[part 2 of 2: packages /ISignalGroups/IMU_INTERNAL/PKG_IMU_INTERNAL/Meas_IMU_B_ST3 to /CryptoDevelopmentKeys]
AUTOSAR XML (schema 00049)
package /ISignalGroups/IMU_INTERNAL/PKG_IMU_INTERNAL/Meas_IMU_B_ST3
  i signal group Meas_IMU_B_ST3_9b4k5uqw790qkzbaaznvwy423: i-signal=[Meas_IMU_B_01_ST3, Meas_IMU_B_02_ST3, Meas_IMU_B_03_ST3, Meas_IMU_B_04_ST3, Meas_IMU_B_05_ST3, Meas_IMU_B_06_ST3, Meas_IMU_B_07_ST3, Meas_IMU_B_08_ST3, Meas_IMU_B_09_ST3, Meas_IMU_B_10_ST3, Meas_IMU_B_11_ST3, Meas_IMU_B_12_ST3, Meas_IMU_B_13_ST3, Meas_IMU_B_14_ST3, Meas_IMU_B_15_ST3, Meas_IMU_B_16_ST3, Meas_IMU_B_17_ST3, Meas_IMU_B_18_ST3, Meas_IMU_B_19_ST3, Meas_IMU_B_20_ST3, Meas_IMU_B_21_ST3, Meas_IMU_B_22_ST3, Meas_IMU_B_23_ST3, Meas_IMU_B_24_ST3, Meas_IMU_B_25_ST3, Meas_IMU_B_26_ST3, Meas_IMU_B_27_ST3, Meas_IMU_B_28_ST3, Meas_IMU_B_29_ST3, Meas_IMU_B_30_ST3, Meas_IMU_B_31_ST3, Meas_IMU_B_32_ST3, Meas_IMU_B_33_ST3, Meas_IMU_B_34_ST3, Meas_IMU_B_35_ST3, Meas_IMU_B_36_ST3, Meas_IMU_B_37_ST3, Meas_IMU_B_38_ST3, Meas_IMU_B_39_ST3, Meas_IMU_B_40_ST3, Meas_IMU_B_41_ST3, Meas_IMU_B_42_ST3, Meas_IMU_B_43_ST3, Meas_IMU_B_44_ST3, Meas_IMU_B_45_ST3, Meas_IMU_B_46_ST3, Meas_IMU_B_47_ST3, Meas_IMU_B_48_ST3, Meas_IMU_B_49_ST3, Meas_IMU_B_50_ST3, Meas_IMU_B_51_ST3, Meas_IMU_B_52_ST3, Meas_IMU_B_53_ST3, Meas_IMU_B_54_ST3, Meas_IMU_B_55_ST3, Meas_IMU_B_56_ST3, Meas_IMU_B_57_ST3, Meas_IMU_B_58_ST3, Meas_IMU_B_59_ST3, Meas_IMU_B_60_ST3, Meas_IMU_B_61_ST3, Meas_IMU_B_62_ST3, Meas_IMU_B_63_ST3, Meas_IMU_B_64_ST3], system-signal-group=Meas_IMU_B_ST3_9b4k5uqw790qkzbaaznvwy423  # Messbotschaft (degraded) / Measurement (degraded)
package /ISignalGroups/IMU_INTERNAL/PKG_IMU_INTERNAL/PT4_PTCoor4_ST3
  i signal group PT4_PTCoor4_Pr5_ST3_af4fxb1ykieox3itqdfzs0kpb: com-based-signal-group-transformations=BaseTrans_Profile_5_4, i-signal=[CRC_PT4_PTCoor4_Pr5_ST3, PT4_PTCoor_EngStartPN14_Stat_ST3, PT4_PTCoor_PT_Rdy_ST3, PT4_PTCoor_SSA_EngSp_ST3, Rsrv1_PT4_PTCoor_PT_Rdy_Pr5_ST3, SQC_PT4_PTCoor4_Pr5_ST3], system-signal-group=PT4_PTCoor4_Pr5_ST3_af4fxb1ykieox3itqdfzs0kpb, end-to-end-transformation-i-signal-props{transformer=E2E_Profile_5, data-ids=196, data-length=32}  # PT4_PTCoor4_Pr5_ST3 (degraded)
package /ISignalGroups/IMU_INTERNAL/PKG_IMU_INTERNAL/ROE_IMU_B_ST3
  i signal group ROE_IMU_B_ST3_7zavpp3siu6s2eitdaqxg7lwg: i-signal=[ROE_0_IMU_B_ST3, ROE_1_IMU_B_ST3, ROE_2_IMU_B_ST3, ROE_3_IMU_B_ST3, ROE_4_IMU_B_ST3, ROE_5_IMU_B_ST3, ROE_6_IMU_B_ST3, ROE_7_IMU_B_ST3], system-signal-group=ROE_IMU_B_ST3_7zavpp3siu6s2eitdaqxg7lwg  # Ereignis-Antwort (degraded) / Response on Event (degraded)
package /ISignalGroups/IMU_INTERNAL/PKG_IMU_INTERNAL/VSS_TP_Auth_ST3
  i signal group VSS_TP_Auth_ST3_6j4id7sghlvlbroli4wjozjik: i-signal=[VSS_TP_Auth_0_ST3, VSS_TP_Auth_1_ST3, VSS_TP_Auth_2_ST3, VSS_TP_Auth_3_ST3, VSS_TP_Auth_4_ST3, VSS_TP_Auth_5_ST3, VSS_TP_Auth_6_ST3, VSS_TP_Auth_7_ST3], system-signal-group=VSS_TP_Auth_ST3_6j4id7sghlvlbroli4wjozjik  # VSS-Transportprotokoll für Authentifizierung (degraded) / Vehicle Security System Transport Protocol for authentication broadcast (degraded)
package /ISignalGroups/IMU_INTERNAL/PKG_IMU_INTERNAL/VSS_TP_RealTmOffset_ST3
  i signal group VSS_TP_RealTmOffset_ST3_1t7vc44gftc0wv35k5kgc2in9: i-signal=[VSS_TP_RealTmOffset_0_ST3, VSS_TP_RealTmOffset_1_ST3, VSS_TP_RealTmOffset_2_ST3, VSS_TP_RealTmOffset_3_ST3, VSS_TP_RealTmOffset_4_ST3, VSS_TP_RealTmOffset_5_ST3, VSS_TP_RealTmOffset_6_ST3, VSS_TP_RealTmOffset_7_ST3], system-signal-group=VSS_TP_RealTmOffset_ST3_1t7vc44gftc0wv35k5kgc2in9  # VSS-Transportprotokoll für Echtzeit-Offset (degraded) / Vehicle Security System Transport Protocol for real time offset broadcast (degraded)
package /ISignalGroups/IMU_INTERNAL/PKG_IMU_INTERNAL/VSS_TP_SecTickCount_Lvl1_ST3
  i signal group VSS_TP_SecTickCount_Lvl1_ST3_mzmfdqtqz5kvv1kfpvg0kql3: i-signal=[VSS_TP_SecTickCount_Lvl1_0_ST3, VSS_TP_SecTickCount_Lvl1_1_ST3, VSS_TP_SecTickCount_Lvl1_2_ST3, VSS_TP_SecTickCount_Lvl1_3_ST3, VSS_TP_SecTickCount_Lvl1_4_ST3, VSS_TP_SecTickCount_Lvl1_5_ST3, VSS_TP_SecTickCount_Lvl1_6_ST3, VSS_TP_SecTickCount_Lvl1_7_ST3], system-signal-group=VSS_TP_SecTickCount_Lvl1_ST3_mzmfdqtqz5kvv1kfpvg0kql3  # VSS-Transportprotokoll für sichere Zeit Stufe 1 (degraded) / Vehicle Security System Transport Protocol for secure tick count level #1 (degraded)
package /ISignalGroups/IMU_INTERNAL/PKG_IMU_INTERNAL/VSS_TP_SharedSecret_ST3
  i signal group VSS_TP_SharedSecret_ST3_8pj4t8t4rm3tw3pk5hj7vonti: i-signal=[VSS_TP_SharedSecret_0_ST3, VSS_TP_SharedSecret_1_ST3, VSS_TP_SharedSecret_2_ST3, VSS_TP_SharedSecret_3_ST3, VSS_TP_SharedSecret_4_ST3, VSS_TP_SharedSecret_5_ST3, VSS_TP_SharedSecret_6_ST3, VSS_TP_SharedSecret_7_ST3], system-signal-group=VSS_TP_SharedSecret_ST3_8pj4t8t4rm3tw3pk5hj7vonti  # VSS-Transportprotokoll für gemeinsames Geheimnis (degraded) / Vehicle Security System Transport Protocol for shared secret broadcast (degraded)
package /ISignalGroups/IMU_INTERNAL/PKG_IMU_INTERNAL/VSS_TP_VIN_ST3
  i signal group VSS_TP_VIN_ST3_bz1xsv84cxzl09j028gn39p69: i-signal=[VSS_TP_VIN_0_ST3, VSS_TP_VIN_1_ST3, VSS_TP_VIN_2_ST3, VSS_TP_VIN_3_ST3, VSS_TP_VIN_4_ST3, VSS_TP_VIN_5_ST3, VSS_TP_VIN_6_ST3, VSS_TP_VIN_7_ST3], system-signal-group=VSS_TP_VIN_ST3_bz1xsv84cxzl09j028gn39p69  # VSS-Transportprotokoll für Fahrzeugidentifikationsnummer (degraded) / Vehicle Security System Transport Protocol for Vehicle Identification Number (degraded)
package /SecureCommunicationPropsSet
  secure communication props set XDIS_singleton_SecCommPropsSet
    secure communication authentication props SECOC_AP_CMAC_AES_128_24: auth-info-tx-length=24
    secure communication freshness props SECOC_FP_10000_40_8_true: freshness-timestamp-time-period-factor=10000, freshness-value-length=40, freshness-value-tx-length=8, use-freshness-timestamp=true
package /CommunicationClusters/IMU_INTERNAL
  can cluster IMU_INTERNAL: baudrate=500000, protocol-name=CAN, protocol-version=can2.0b, can-fd-baudrate=1000000
    can physical channel IMU_INTERNAL: comm-connectors=[IMU_A_IMU_INTERNAL_6hr0dxrs6bxnusth9n7j0x4yv, IMU_B_IMU_INTERNAL_949amicgr3ot53d5rms7k8b3w]
      frame FBL_CFG_Star3_ST3: id 0x68, from IMU_A, to IMU_B, frame-length=1, can-addressing-mode=STANDARD, can-frame-rx-behavior=CAN-20, can-frame-tx-behavior=CAN-20
        pdu FBL_Cfg_Star3_ST3: length=1, transmission-mode-true-timing=cyclic-timing=time-period=0.2, unused-bit-pattern=255  # FBL Konfigurationsinfo für Star3 / FBL configuration info for Star3
          signal Platform_Stat_Star3: start 0, 8 bit, little-endian, data-type-policy=OVERRIDE, i-signal-type=PRIMITIVE, init-value=4, base-type=uint8, invalid-value=255, compu-method=c08_Platform_Stat, data-constr=c08_Platform_Stat, transfer-property=PENDING, to IMU_B  # Plattformstatus / Platform state
      frame GTS_Main_CAN_ST3: id 0x79, from IMU_A, to IMU_B, frame-length=8, can-addressing-mode=STANDARD, can-frame-rx-behavior=CAN-FD, can-frame-tx-behavior=CAN-FD  # Status Uhrsynchronisation / Clock synchronisation state
        carries pdu GTS_Main_CAN_ST3: packing-byte-order=big-endian, start-position=7
        general purpose pdu GTS_Main_CAN_ST3: category=GLOBAL_TIME, length=8  # Status Uhrsynchronisation / Clock synchronisation state
      frame Ign_Stat_ST3: id 0x7F, from IMU_A, to IMU_B, frame-length=8, can-addressing-mode=STANDARD, can-frame-rx-behavior=CAN-FD, can-frame-tx-behavior=CAN-FD  # Zuendungsstatus / Ignition state
        secured i pdu Ign_Stat_ST3_secured: length=8, authentication-props=SECOC_AP_CMAC_AES_128_24, freshness-props=SECOC_FP_10000_40_8_true, payload=Ign_Stat_ST3_74u0yv4bzub4d7kkohk0jy10a, secure-communication-props={authentication-retries=0, data-id=28212, freshness-value-id=1}
      frame IMU_A_Output_Fast_ST3: id 0x2B3, from IMU_A, to IMU_B, frame-length=44, can-addressing-mode=STANDARD, can-frame-rx-behavior=CAN-FD, can-frame-tx-behavior=CAN-FD  # IMU A Output ST3
        secured i pdu IMU_A_Output_Fast_ST3_secured: length=44, authentication-props=SECOC_AP_CMAC_AES_128_24, freshness-props=SECOC_FP_10000_40_8_true, payload=IMU_A_Output_Fast_ST3_9j5x7ag429n202ymo68kf1vn0, secure-communication-props={authentication-retries=0, data-id=38379, freshness-value-id=1}
      frame BCS_Whl_Msg1_BTC_ST3: id 0x2BE, from IMU_A, to IMU_B, frame-length=24, can-addressing-mode=STANDARD, can-frame-rx-behavior=CAN-FD, can-frame-tx-behavior=CAN-FD  # BCS Whl Msg 1 ST3
        secured i pdu BCS_Whl_Msg1_BTC_ST3_secured: length=24, authentication-props=SECOC_AP_CMAC_AES_128_24, freshness-props=SECOC_FP_10000_40_8_true, payload=BCS_Whl_Msg1_BTC_ST3_c16k4ur8udt67j57b0rf78j53, secure-communication-props={authentication-retries=0, data-id=1270, freshness-value-id=1}
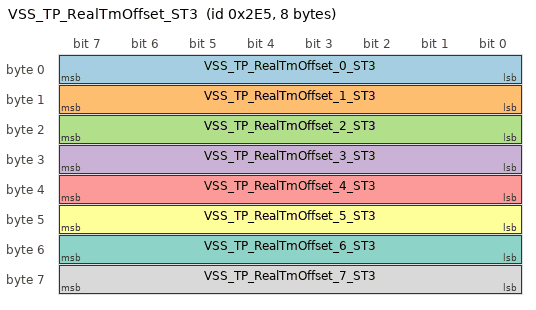
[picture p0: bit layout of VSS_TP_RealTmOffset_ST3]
      frame VSS_TP_RealTmOffset_ST3: id 0x2E5, from IMU_A, to IMU_B, frame-length=8, can-addressing-mode=STANDARD, can-frame-rx-behavior=CAN-FD, can-frame-tx-behavior=CAN-FD  # VSS-Transportprotokoll für Echtzeit-Offset / Vehicle Security System Transport Protocol for real time offset broadcast
        pdu VSS_TP_RealTmOffset_ST3: length=8, minimum-delay=0.02, transmission-mode-true-timing=event-controlled-timing=number-of-repetitions=0, unused-bit-pattern=255  # VSS-Transportprotokoll für Echtzeit-Offset / Vehicle Security System Transport Protocol for real time offset broadcast
          signal VSS_TP_RealTmOffset_0_ST3: start 0, 8 bit, little-endian, data-type-policy=OVERRIDE, i-signal-type=PRIMITIVE, init-value=255, base-type=uint8, data-constr=c08_UInt_SNA_na, to IMU_B  # VSS-Transportprotokoll für Echtzeit-Offset, Byte 0 / Vehicle Security System Transport Protocol for real time offset broadcast, Byte 0
          signal VSS_TP_RealTmOffset_1_ST3: start 8, 8 bit, little-endian, data-type-policy=OVERRIDE, i-signal-type=PRIMITIVE, init-value=255, base-type=uint8, data-constr=c08_UInt_SNA_na, to IMU_B  # VSS-Transportprotokoll für Echtzeit-Offset, Byte 1 / Vehicle Security System Transport Protocol for real time offset broadcast, Byte 1
          signal VSS_TP_RealTmOffset_2_ST3: start 16, 8 bit, little-endian, data-type-policy=OVERRIDE, i-signal-type=PRIMITIVE, init-value=255, base-type=uint8, data-constr=c08_UInt_SNA_na, to IMU_B  # VSS-Transportprotokoll für Echtzeit-Offset, Byte 2 / Vehicle Security System Transport Protocol for real time offset broadcast, Byte 2
          signal VSS_TP_RealTmOffset_3_ST3: start 24, 8 bit, little-endian, data-type-policy=OVERRIDE, i-signal-type=PRIMITIVE, init-value=255, base-type=uint8, data-constr=c08_UInt_SNA_na, to IMU_B  # VSS-Transportprotokoll für Echtzeit-Offset, Byte 3 / Vehicle Security System Transport Protocol for real time offset broadcast, Byte 3
          signal VSS_TP_RealTmOffset_4_ST3: start 32, 8 bit, little-endian, data-type-policy=OVERRIDE, i-signal-type=PRIMITIVE, init-value=255, base-type=uint8, data-constr=c08_UInt_SNA_na, to IMU_B  # VSS-Transportprotokoll für Echtzeit-Offset, Byte 4 / Vehicle Security System Transport Protocol for real time offset broadcast, Byte 4
          signal VSS_TP_RealTmOffset_5_ST3: start 40, 8 bit, little-endian, data-type-policy=OVERRIDE, i-signal-type=PRIMITIVE, init-value=255, base-type=uint8, data-constr=c08_UInt_SNA_na, to IMU_B  # VSS-Transportprotokoll für Echtzeit-Offset, Byte 5 / Vehicle Security System Transport Protocol for real time offset broadcast, Byte 5
          signal VSS_TP_RealTmOffset_6_ST3: start 48, 8 bit, little-endian, data-type-policy=OVERRIDE, i-signal-type=PRIMITIVE, init-value=255, base-type=uint8, data-constr=c08_UInt_SNA_na, to IMU_B  # VSS-Transportprotokoll für Echtzeit-Offset, Byte 6 / Vehicle Security System Transport Protocol for real time offset broadcast, Byte 6
          signal VSS_TP_RealTmOffset_7_ST3: start 56, 8 bit, little-endian, data-type-policy=OVERRIDE, i-signal-type=PRIMITIVE, init-value=255, base-type=uint8, data-constr=c08_UInt_SNA_na, to IMU_B  # VSS-Transportprotokoll für Echtzeit-Offset, Byte 7 / Vehicle Security System Transport Protocol for real time offset broadcast, Byte 7
          mapping VSS_TP_RealTmOffset_ST3_1t7vc44gftc0wv35k5kgc2in9: i-signal-group=VSS_TP_RealTmOffset_ST3_1t7vc44gftc0wv35k5kgc2in9, packing-byte-order=little-endian, transfer-property=TRIGGERED
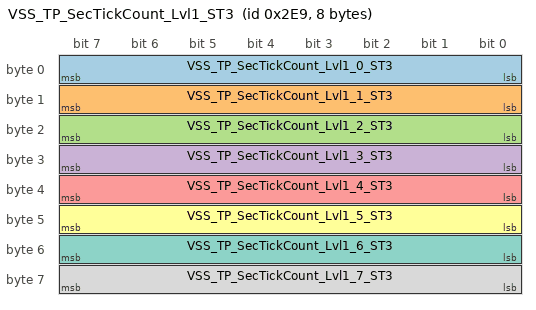
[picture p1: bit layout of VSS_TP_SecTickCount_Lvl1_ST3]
      frame VSS_TP_SecTickCount_Lvl1_ST3: id 0x2E9, from IMU_A, to IMU_B, frame-length=8, can-addressing-mode=STANDARD, can-frame-rx-behavior=CAN-FD, can-frame-tx-behavior=CAN-FD  # VSS-Transportprotokoll für sichere Zeit Stufe 1 / Vehicle Security System Transport Protocol for secure tick count level #1
        pdu VSS_TP_SecTickCount_Lvl1_ST3: length=8, minimum-delay=0.02, transmission-mode-true-timing=event-controlled-timing=number-of-repetitions=0, unused-bit-pattern=255  # VSS-Transportprotokoll für sichere Zeit Stufe 1 / Vehicle Security System Transport Protocol for secure tick count level #1
          signal VSS_TP_SecTickCount_Lvl1_0_ST3: start 0, 8 bit, little-endian, data-type-policy=OVERRIDE, i-signal-type=PRIMITIVE, init-value=255, base-type=uint8, data-constr=c08_UInt_SNA_na, to IMU_B  # VSS-Transportprotokoll für sichere Zeit Stufe 1, Byte 0 / Vehicle Security System Transport Protocol for secure tick count level #1, Byte 0
          signal VSS_TP_SecTickCount_Lvl1_1_ST3: start 8, 8 bit, little-endian, data-type-policy=OVERRIDE, i-signal-type=PRIMITIVE, init-value=255, base-type=uint8, data-constr=c08_UInt_SNA_na, to IMU_B  # VSS-Transportprotokoll für sichere Zeit Stufe 1, Byte 1 / Vehicle Security System Transport Protocol for secure tick count level #1, Byte 1
          signal VSS_TP_SecTickCount_Lvl1_2_ST3: start 16, 8 bit, little-endian, data-type-policy=OVERRIDE, i-signal-type=PRIMITIVE, init-value=255, base-type=uint8, data-constr=c08_UInt_SNA_na, to IMU_B  # VSS-Transportprotokoll für sichere Zeit Stufe 1, Byte 2 / Vehicle Security System Transport Protocol for secure tick count level #1, Byte 2
          signal VSS_TP_SecTickCount_Lvl1_3_ST3: start 24, 8 bit, little-endian, data-type-policy=OVERRIDE, i-signal-type=PRIMITIVE, init-value=255, base-type=uint8, data-constr=c08_UInt_SNA_na, to IMU_B  # VSS-Transportprotokoll für sichere Zeit Stufe 1, Byte 3 / Vehicle Security System Transport Protocol for secure tick count level #1, Byte 3
          signal VSS_TP_SecTickCount_Lvl1_4_ST3: start 32, 8 bit, little-endian, data-type-policy=OVERRIDE, i-signal-type=PRIMITIVE, init-value=255, base-type=uint8, data-constr=c08_UInt_SNA_na, to IMU_B  # VSS-Transportprotokoll für sichere Zeit Stufe 1, Byte 4 / Vehicle Security System Transport Protocol for secure tick count level #1, Byte 4
          signal VSS_TP_SecTickCount_Lvl1_5_ST3: start 40, 8 bit, little-endian, data-type-policy=OVERRIDE, i-signal-type=PRIMITIVE, init-value=255, base-type=uint8, data-constr=c08_UInt_SNA_na, to IMU_B  # VSS-Transportprotokoll für sichere Zeit Stufe 1, Byte 5 / Vehicle Security System Transport Protocol for secure tick count level #1, Byte 5
          signal VSS_TP_SecTickCount_Lvl1_6_ST3: start 48, 8 bit, little-endian, data-type-policy=OVERRIDE, i-signal-type=PRIMITIVE, init-value=255, base-type=uint8, data-constr=c08_UInt_SNA_na, to IMU_B  # VSS-Transportprotokoll für sichere Zeit Stufe 1, Byte 6 / Vehicle Security System Transport Protocol for secure tick count level #1, Byte 6
          signal VSS_TP_SecTickCount_Lvl1_7_ST3: start 56, 8 bit, little-endian, data-type-policy=OVERRIDE, i-signal-type=PRIMITIVE, init-value=255, base-type=uint8, data-constr=c08_UInt_SNA_na, to IMU_B  # VSS-Transportprotokoll für sichere Zeit Stufe 1, Byte 7 / Vehicle Security System Transport Protocol for secure tick count level #1, Byte 7
          mapping VSS_TP_SecTickCount_Lvl1_ST3_mzmfdqtqz5kvv1kfpvg0kql3: i-signal-group=VSS_TP_SecTickCount_Lvl1_ST3_mzmfdqtqz5kvv1kfpvg0kql3, packing-byte-order=little-endian, transfer-property=TRIGGERED
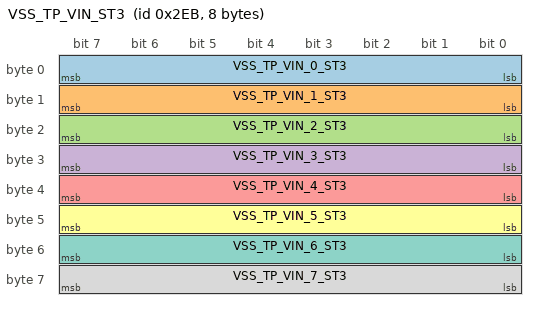
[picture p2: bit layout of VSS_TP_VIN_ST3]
      frame VSS_TP_VIN_ST3: id 0x2EB, from IMU_A, to IMU_B, frame-length=8, can-addressing-mode=STANDARD, can-frame-rx-behavior=CAN-FD, can-frame-tx-behavior=CAN-FD  # VSS-Transportprotokoll für Fahrzeugidentifikationsnummer / Vehicle Security System Transport Protocol for Vehicle Identification Number
        pdu VSS_TP_VIN_ST3: length=8, minimum-delay=0.02, transmission-mode-true-timing=event-controlled-timing=number-of-repetitions=0, unused-bit-pattern=255  # VSS-Transportprotokoll für Fahrzeugidentifikationsnummer / Vehicle Security System Transport Protocol for Vehicle Identification Number
          signal VSS_TP_VIN_0_ST3: start 0, 8 bit, little-endian, data-type-policy=OVERRIDE, i-signal-type=PRIMITIVE, init-value=63, base-type=uint8, data-constr=c08_UInt_SNA_na, to IMU_B  # VSS-Transportprotokoll für Fahrzeugidentifikationsnummer, Byte 0 / Vehicle Security System Transport Protocol for Vehicle Identification Number, Byte 0
          signal VSS_TP_VIN_1_ST3: start 8, 8 bit, little-endian, data-type-policy=OVERRIDE, i-signal-type=PRIMITIVE, init-value=63, base-type=uint8, data-constr=c08_UInt_SNA_na, to IMU_B  # VSS-Transportprotokoll für Fahrzeugidentifikationsnummer, Byte 1 / Vehicle Security System Transport Protocol for Vehicle Identification Number, Byte 1
          signal VSS_TP_VIN_2_ST3: start 16, 8 bit, little-endian, data-type-policy=OVERRIDE, i-signal-type=PRIMITIVE, init-value=63, base-type=uint8, data-constr=c08_UInt_SNA_na, to IMU_B  # VSS-Transportprotokoll für Fahrzeugidentifikationsnummer, Byte 2 / Vehicle Security System Transport Protocol for Vehicle Identification Number, Byte 2
          signal VSS_TP_VIN_3_ST3: start 24, 8 bit, little-endian, data-type-policy=OVERRIDE, i-signal-type=PRIMITIVE, init-value=63, base-type=uint8, data-constr=c08_UInt_SNA_na, to IMU_B  # VSS-Transportprotokoll für Fahrzeugidentifikationsnummer, Byte 3 / Vehicle Security System Transport Protocol for Vehicle Identification Number, Byte 3
          signal VSS_TP_VIN_4_ST3: start 32, 8 bit, little-endian, data-type-policy=OVERRIDE, i-signal-type=PRIMITIVE, init-value=63, base-type=uint8, data-constr=c08_UInt_SNA_na, to IMU_B  # VSS-Transportprotokoll für Fahrzeugidentifikationsnummer, Byte 4 / Vehicle Security System Transport Protocol for Vehicle Identification Number, Byte 4
          signal VSS_TP_VIN_5_ST3: start 40, 8 bit, little-endian, data-type-policy=OVERRIDE, i-signal-type=PRIMITIVE, init-value=63, base-type=uint8, data-constr=c08_UInt_SNA_na, to IMU_B  # VSS-Transportprotokoll für Fahrzeugidentifikationsnummer, Byte 5 / Vehicle Security System Transport Protocol for Vehicle Identification Number, Byte 5
          signal VSS_TP_VIN_6_ST3: start 48, 8 bit, little-endian, data-type-policy=OVERRIDE, i-signal-type=PRIMITIVE, init-value=63, base-type=uint8, data-constr=c08_UInt_SNA_na, to IMU_B  # VSS-Transportprotokoll für Fahrzeugidentifikationsnummer, Byte 6 / Vehicle Security System Transport Protocol for Vehicle Identification Number, Byte 6
          signal VSS_TP_VIN_7_ST3: start 56, 8 bit, little-endian, data-type-policy=OVERRIDE, i-signal-type=PRIMITIVE, init-value=63, base-type=uint8, data-constr=c08_UInt_SNA_na, to IMU_B  # VSS-Transportprotokoll für Fahrzeugidentifikationsnummer, Byte 7 / Vehicle Security System Transport Protocol for Vehicle Identification Number, Byte 7
          mapping VSS_TP_VIN_ST3_bz1xsv84cxzl09j028gn39p69: i-signal-group=VSS_TP_VIN_ST3_bz1xsv84cxzl09j028gn39p69, packing-byte-order=little-endian, transfer-property=TRIGGERED
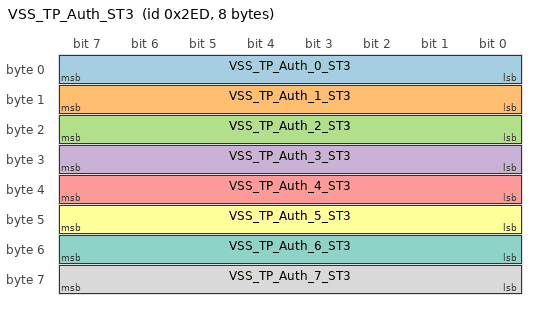
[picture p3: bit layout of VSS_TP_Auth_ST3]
      frame VSS_TP_Auth_ST3: id 0x2ED, from IMU_A, to IMU_B, frame-length=8, can-addressing-mode=STANDARD, can-frame-rx-behavior=CAN-FD, can-frame-tx-behavior=CAN-FD  # VSS-Transportprotokoll für Authentifizierung / Vehicle Security System Transport Protocol for authentication broadcast
        pdu VSS_TP_Auth_ST3: length=8, minimum-delay=0.02, transmission-mode-true-timing=event-controlled-timing=number-of-repetitions=0, unused-bit-pattern=255  # VSS-Transportprotokoll für Authentifizierung / Vehicle Security System Transport Protocol for authentication broadcast
          signal VSS_TP_Auth_0_ST3: start 0, 8 bit, little-endian, data-type-policy=OVERRIDE, i-signal-type=PRIMITIVE, init-value=255, base-type=uint8, data-constr=c08_UInt_SNA_na, to IMU_B  # VSS-Transportprotokoll für Authentifizierung, Byte 0 / Vehicle Security System Transport Protocol for authentication broadcast, Byte 0
          signal VSS_TP_Auth_1_ST3: start 8, 8 bit, little-endian, data-type-policy=OVERRIDE, i-signal-type=PRIMITIVE, init-value=255, base-type=uint8, data-constr=c08_UInt_SNA_na, to IMU_B  # VSS-Transportprotokoll für Authentifizierung, Byte 1 / Vehicle Security System Transport Protocol for authentication broadcast, Byte 1
          signal VSS_TP_Auth_2_ST3: start 16, 8 bit, little-endian, data-type-policy=OVERRIDE, i-signal-type=PRIMITIVE, init-value=255, base-type=uint8, data-constr=c08_UInt_SNA_na, to IMU_B  # VSS-Transportprotokoll für Authentifizierung, Byte 2 / Vehicle Security System Transport Protocol for authentication broadcast, Byte 2
          signal VSS_TP_Auth_3_ST3: start 24, 8 bit, little-endian, data-type-policy=OVERRIDE, i-signal-type=PRIMITIVE, init-value=255, base-type=uint8, data-constr=c08_UInt_SNA_na, to IMU_B  # VSS-Transportprotokoll für Authentifizierung, Byte 3 / Vehicle Security System Transport Protocol for authentication broadcast, Byte 3
          signal VSS_TP_Auth_4_ST3: start 32, 8 bit, little-endian, data-type-policy=OVERRIDE, i-signal-type=PRIMITIVE, init-value=255, base-type=uint8, data-constr=c08_UInt_SNA_na, to IMU_B  # VSS-Transportprotokoll für Authentifizierung, Byte 4 / Vehicle Security System Transport Protocol for authentication broadcast, Byte 4
          signal VSS_TP_Auth_5_ST3: start 40, 8 bit, little-endian, data-type-policy=OVERRIDE, i-signal-type=PRIMITIVE, init-value=255, base-type=uint8, data-constr=c08_UInt_SNA_na, to IMU_B  # VSS-Transportprotokoll für Authentifizierung, Byte 5 / Vehicle Security System Transport Protocol for authentication broadcast, Byte 5
          signal VSS_TP_Auth_6_ST3: start 48, 8 bit, little-endian, data-type-policy=OVERRIDE, i-signal-type=PRIMITIVE, init-value=255, base-type=uint8, data-constr=c08_UInt_SNA_na, to IMU_B  # VSS-Transportprotokoll für Authentifizierung, Byte 6 / Vehicle Security System Transport Protocol for authentication broadcast, Byte 6
          signal VSS_TP_Auth_7_ST3: start 56, 8 bit, little-endian, data-type-policy=OVERRIDE, i-signal-type=PRIMITIVE, init-value=255, base-type=uint8, data-constr=c08_UInt_SNA_na, to IMU_B  # VSS-Transportprotokoll für Authentifizierung, Byte 7 / Vehicle Security System Transport Protocol for authentication broadcast, Byte 7
          mapping VSS_TP_Auth_ST3_6j4id7sghlvlbroli4wjozjik: i-signal-group=VSS_TP_Auth_ST3_6j4id7sghlvlbroli4wjozjik, packing-byte-order=little-endian, transfer-property=TRIGGERED
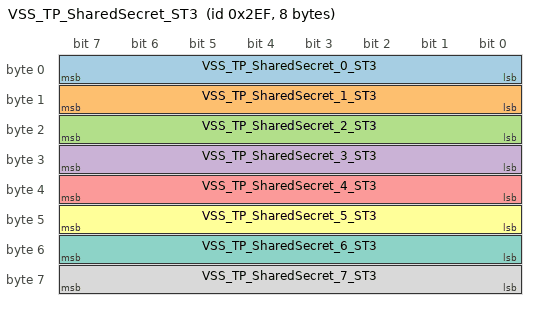
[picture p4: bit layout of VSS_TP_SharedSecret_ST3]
      frame VSS_TP_SharedSecret_ST3: id 0x2EF, from IMU_A, to IMU_B, frame-length=8, can-addressing-mode=STANDARD, can-frame-rx-behavior=CAN-FD, can-frame-tx-behavior=CAN-FD  # VSS-Transportprotokoll für gemeinsames Geheimnis / Vehicle Security System Transport Protocol for shared secret broadcast
        pdu VSS_TP_SharedSecret_ST3: length=8, minimum-delay=0.02, transmission-mode-true-timing=event-controlled-timing=number-of-repetitions=0, unused-bit-pattern=255  # VSS-Transportprotokoll für gemeinsames Geheimnis / Vehicle Security System Transport Protocol for shared secret broadcast
          signal VSS_TP_SharedSecret_0_ST3: start 0, 8 bit, little-endian, data-type-policy=OVERRIDE, i-signal-type=PRIMITIVE, init-value=255, base-type=uint8, data-constr=c08_UInt_SNA_na, to IMU_B  # VSS-Transportprotokoll für gemeinsames Geheimnis, Byte 0 / Vehicle Security System Transport Protocol for shared secret broadcast, Byte 0
          signal VSS_TP_SharedSecret_1_ST3: start 8, 8 bit, little-endian, data-type-policy=OVERRIDE, i-signal-type=PRIMITIVE, init-value=255, base-type=uint8, data-constr=c08_UInt_SNA_na, to IMU_B  # VSS-Transportprotokoll für gemeinsames Geheimnis, Byte 1 / Vehicle Security System Transport Protocol for shared secret broadcast, Byte 1
          signal VSS_TP_SharedSecret_2_ST3: start 16, 8 bit, little-endian, data-type-policy=OVERRIDE, i-signal-type=PRIMITIVE, init-value=255, base-type=uint8, data-constr=c08_UInt_SNA_na, to IMU_B  # VSS-Transportprotokoll für gemeinsames Geheimnis, Byte 2 / Vehicle Security System Transport Protocol for shared secret broadcast, Byte 2
          signal VSS_TP_SharedSecret_3_ST3: start 24, 8 bit, little-endian, data-type-policy=OVERRIDE, i-signal-type=PRIMITIVE, init-value=255, base-type=uint8, data-constr=c08_UInt_SNA_na, to IMU_B  # VSS-Transportprotokoll für gemeinsames Geheimnis, Byte 3 / Vehicle Security System Transport Protocol for shared secret broadcast, Byte 3
          signal VSS_TP_SharedSecret_4_ST3: start 32, 8 bit, little-endian, data-type-policy=OVERRIDE, i-signal-type=PRIMITIVE, init-value=255, base-type=uint8, data-constr=c08_UInt_SNA_na, to IMU_B  # VSS-Transportprotokoll für gemeinsames Geheimnis, Byte 4 / Vehicle Security System Transport Protocol for shared secret broadcast, Byte 4
          signal VSS_TP_SharedSecret_5_ST3: start 40, 8 bit, little-endian, data-type-policy=OVERRIDE, i-signal-type=PRIMITIVE, init-value=255, base-type=uint8, data-constr=c08_UInt_SNA_na, to IMU_B  # VSS-Transportprotokoll für gemeinsames Geheimnis, Byte 5 / Vehicle Security System Transport Protocol for shared secret broadcast, Byte 5
          signal VSS_TP_SharedSecret_6_ST3: start 48, 8 bit, little-endian, data-type-policy=OVERRIDE, i-signal-type=PRIMITIVE, init-value=255, base-type=uint8, data-constr=c08_UInt_SNA_na, to IMU_B  # VSS-Transportprotokoll für gemeinsames Geheimnis, Byte 6 / Vehicle Security System Transport Protocol for shared secret broadcast, Byte 6
          signal VSS_TP_SharedSecret_7_ST3: start 56, 8 bit, little-endian, data-type-policy=OVERRIDE, i-signal-type=PRIMITIVE, init-value=255, base-type=uint8, data-constr=c08_UInt_SNA_na, to IMU_B  # VSS-Transportprotokoll für gemeinsames Geheimnis, Byte 7 / Vehicle Security System Transport Protocol for shared secret broadcast, Byte 7
          mapping VSS_TP_SharedSecret_ST3_8pj4t8t4rm3tw3pk5hj7vonti: i-signal-group=VSS_TP_SharedSecret_ST3_8pj4t8t4rm3tw3pk5hj7vonti, packing-byte-order=little-endian, transfer-property=TRIGGERED
      frame IMU_B_Output_ST3: id 0x3A6, from IMU_B, to IMU_A, frame-length=44, can-addressing-mode=STANDARD, can-frame-rx-behavior=CAN-FD, can-frame-tx-behavior=CAN-FD  # IMU B Output ST3
        secured i pdu IMU_B_Output_ST3_secured: length=44, authentication-props=SECOC_AP_CMAC_AES_128_24, freshness-props=SECOC_FP_10000_40_8_true, payload=IMU_B_Output_ST3_71wg165b3j1a1mormsg5xnlfr, secure-communication-props={authentication-retries=0, data-id=46116, freshness-value-id=1}
      frame PT4_PTCoor4_SecOC_ST3: id 0x519, from IMU_A, to IMU_B, frame-length=8, can-addressing-mode=STANDARD, can-frame-rx-behavior=CAN-FD, can-frame-tx-behavior=CAN-FD
        secured i pdu PT4_PTCoor4_ST3_secured: length=8, authentication-props=SECOC_AP_CMAC_AES_128_24, freshness-props=SECOC_FP_10000_40_8_true, payload=PT4_PTCoor4_ST3_831x3bc2a5f0b8lcc0rs7f0hl, secure-communication-props={authentication-retries=0, data-id=26743, freshness-value-id=1}
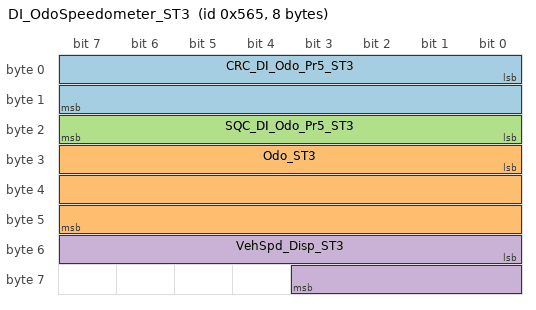
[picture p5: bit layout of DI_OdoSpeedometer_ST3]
      frame DI_OdoSpeedometer_ST3: id 0x565, from IMU_A, to IMU_B, frame-length=8, can-addressing-mode=STANDARD, can-frame-rx-behavior=CAN-FD, can-frame-tx-behavior=CAN-FD  # Fahrerinformation Odometer und Tacho / DriverInformation Odometer and speedometer
        pdu DI_OdoSpeedometer_ST3: length=8, minimum-delay=0.1, transmission-mode-true-timing={cyclic-timing=time-period=1.0, event-controlled-timing=number-of-repetitions=0}, unused-bit-pattern=255  # Fahrerinformation Odometer und Tacho / DriverInformation Odometer and speedometer
          signal CRC_DI_Odo_Pr5_ST3: start 0, 16 bit, little-endian, data-type-policy=OVERRIDE, i-signal-type=PRIMITIVE, init-value=8633, base-type=uint16, data-constr=c16_CRC_woSNA, transfer-property=PENDING, to IMU_B  # CRC-Checksumme der Signal Gruppe gemäß AUTOSAR Profil 5 / CRC-checksum of signal group according to AUTOSAR Profile 5
          signal Odo_ST3: start 24, 24 bit, little-endian, data-type-policy=OVERRIDE, i-signal-type=PRIMITIVE, init-value=16777215, base-type=uint32, invalid-value=16777215, compu-method=c24_km_0_999999k9_0k1_Invld_SNA, data-constr=c24_km_0_999999k9_0k1_Invld_SNA, transfer-property=TRIGGERED-ON-CHANGE, to IMU_B  # Kilometerstand (für alle) / Odometer (for everyone)
          signal SQC_DI_Odo_Pr5_ST3: start 16, 8 bit, little-endian, data-type-policy=OVERRIDE, i-signal-type=PRIMITIVE, init-value=0, base-type=uint8, compu {identical}, data-constr=c08_0_255_1_SNA_na, transfer-property=PENDING, to IMU_B  # Sequenzzähler / Sequence counter
          signal VehSpd_Disp_ST3: start 48, 12 bit, little-endian, data-type-policy=OVERRIDE, i-signal-type=PRIMITIVE, init-value=4095, base-type=uint16, invalid-value=4095, compu-method=c12_km_p_h_0_409k4_0k1, data-constr=c12_km_p_h_0_409k4_0k1, transfer-property=TRIGGERED-ON-CHANGE, to IMU_B  # NICHT MEHR VERWENDEN/LÄUFT zu MB.EA-L AUS!!! Bitte VehSpd_X_Disp_Rq_ST3 verwenden ------ Angezeigte Geschwindigkeit (ohne Zeigerdämpfung) / DONT USE/EOL is MB.EA-L!!! Use VehSpd_X_Disp_Rq_ST3 instead ------ Displayed vehicle speed (without attenuation)
          mapping DI_Odo_Pr5_ST3_e68xmtlkywxgxsdwekdjjhw3t: i-signal-group=DI_Odo_Pr5_ST3_e68xmtlkywxgxsdwekdjjhw3t, packing-byte-order=little-endian, transfer-property=TRIGGERED-ON-CHANGE, update-indication-bit-position=63
      frame PN14_Master_Stat1_SecOC_ST3: id 0x5E8, from IMU_A, to IMU_B, frame-length=12, can-addressing-mode=STANDARD, can-frame-rx-behavior=CAN-FD, can-frame-tx-behavior=CAN-FD  # Status 12V Bordnetz Master / Powernetwork 12V master state
        secured i pdu PN14_Master_Stat1_ST3_secured: length=12, authentication-props=SECOC_AP_CMAC_AES_128_24, freshness-props=SECOC_FP_10000_40_8_true, payload=PN14_Master_Stat1_ST3_2eb8i7df9hluel7u1vtmv4jbu, secure-communication-props={authentication-retries=0, data-id=57668, freshness-value-id=1}
      frame DIAG_Stat_ST3: id 0x6D0, from IMU_A, to IMU_B, frame-length=4, can-addressing-mode=STANDARD, can-frame-rx-behavior=CAN-FD, can-frame-tx-behavior=CAN-FD  # Actv Line Status Tester pres / Actv Line state Tester pres
        pdu DIAG_Stat_ST3: length=4, minimum-delay=0.04, transmission-mode-true-timing={cyclic-timing=time-period=1.0, event-controlled-timing=number-of-repetitions=0}, unused-bit-pattern=255  # Actv Line Status Tester pres / Actv Line state Tester pres
          signal Actv_Line_Stat_ST3: start 0, 2 bit, little-endian, data-type-policy=OVERRIDE, i-signal-type=PRIMITIVE, init-value=0, base-type=uint8, invalid-value=3, compu-method=c02_Inact_Act_ST3, data-constr=c02_Inact_Act_ST3, transfer-property=TRIGGERED-ON-CHANGE  # Aktivierungs Leitungsstatus / Activation Line state
          signal DidA_ExtTest_Pres_ST3: start 2, 2 bit, little-endian, data-type-policy=OVERRIDE, i-signal-type=PRIMITIVE, init-value=3, base-type=uint8, invalid-value=3, compu-method=c02_Ndef_False_True_ST3, data-constr=c02_Ndef_False_True_ST3, transfer-property=TRIGGERED-ON-CHANGE, to IMU_B  # DidA Externer Tester erkannt / DidA external tester present
      frame NM_IMU_A_ST3: id 0x1442016A, from IMU_A, frame-length=8, can-addressing-mode=EXTENDED, can-frame-rx-behavior=CAN-20, can-frame-tx-behavior=CAN-20  # Netzwerk-Management / Network Management
        nm pdu NM_IMU_A_ST3: length=8, nm-data-information=true, unused-bit-pattern=0  # STAR3 NM PDU
          signal NM_ActvWakeup: start 4, 1 bit, little-endian, data-type-policy=OVERRIDE, i-signal-type=PRIMITIVE, init-value=0, base-type=boolean, transfer-property=PENDING  # Active Wakeup Bit
          signal NM_Coord_Id: start 1, 2 bit, little-endian, data-type-policy=OVERRIDE, i-signal-type=PRIMITIVE, init-value=0, base-type=uint8, range raw 0..3, transfer-property=PENDING  # NM Coordinator ID
          signal NM_Coord_SleepRdy: start 3, 1 bit, little-endian, data-type-policy=OVERRIDE, i-signal-type=PRIMITIVE, init-value=0, base-type=boolean, transfer-property=PENDING  # NM Coordinator Sleep Ready Bit
          signal NM_PartNw_Info: start 6, 1 bit, little-endian, data-type-policy=OVERRIDE, i-signal-type=PRIMITIVE, init-value=0, base-type=boolean, transfer-property=PENDING  # Partial Network Information Bit
          signal NM_RepeatMsg_Rq: start 0, 1 bit, little-endian, data-type-policy=OVERRIDE, i-signal-type=PRIMITIVE, init-value=0, base-type=boolean, transfer-property=PENDING  # Repeat Message Request
          signal PNC_00_All_Active_ST3: start 8, 1 bit, little-endian, data-type-policy=OVERRIDE, i-signal-type=PRIMITIVE, init-value=0, base-type=boolean, transfer-property=PENDING  # PNC All Active
          signal PNC_01_HV_Charging_ST3: start 9, 1 bit, little-endian, data-type-policy=OVERRIDE, i-signal-type=PRIMITIVE, init-value=0, base-type=boolean, transfer-property=PENDING  # PNC Hochspannungsladen / PNC high voltage charging
          signal PNC_02_Recharge_Mode_HV_12V_ST3: start 10, 1 bit, little-endian, data-type-policy=OVERRIDE, i-signal-type=PRIMITIVE, init-value=0, base-type=boolean, transfer-property=PENDING  # PNC Umladen zwischen Hochspannung und 12V / PNC recharge betweeen high voltage and 12V
          signal PNC_03_Preconditioning_ST3: start 11, 1 bit, little-endian, data-type-policy=OVERRIDE, i-signal-type=PRIMITIVE, init-value=0, base-type=boolean, transfer-property=PENDING  # PNC Vorkonditionierung / PNC Preconditioning
          signal PNC_04_Telematics_Standalone_ST3: start 12, 1 bit, little-endian, data-type-policy=OVERRIDE, i-signal-type=PRIMITIVE, init-value=0, base-type=boolean, transfer-property=PENDING  # PNC Telematic standalone
          signal PNC_05_Warning_Lights_ST3: start 13, 1 bit, little-endian, data-type-policy=OVERRIDE, i-signal-type=PRIMITIVE, init-value=0, base-type=boolean, transfer-property=PENDING  # PNC Warnblinker / PNC Warning lights
          signal PNC_06_Exit_Warning_ST3: start 14, 1 bit, little-endian, data-type-policy=OVERRIDE, i-signal-type=PRIMITIVE, init-value=0, base-type=boolean, transfer-property=PENDING  # PNC Ausstiegswarnung / PNC Exit warning
          signal PNC_07_SeatComfort_ST3: start 15, 1 bit, little-endian, data-type-policy=OVERRIDE, i-signal-type=PRIMITIVE, init-value=0, base-type=boolean, transfer-property=PENDING  # PNC_07 Seat Comfort
          signal PNC_08_Telematics_Communication_ST3: start 16, 1 bit, little-endian, data-type-policy=OVERRIDE, i-signal-type=PRIMITIVE, init-value=0, base-type=boolean, transfer-property=PENDING  # PNC Telematics communication
          signal PNC_09_IDC_Standalone_ST3: start 17, 1 bit, little-endian, data-type-policy=OVERRIDE, i-signal-type=PRIMITIVE, init-value=0, base-type=boolean, transfer-property=PENDING  # PNC IDC Standalone
          signal PNC_10_Inside_Temp_ST3: start 18, 1 bit, little-endian, data-type-policy=OVERRIDE, i-signal-type=PRIMITIVE, init-value=0, base-type=boolean, transfer-property=PENDING  # PNC Innentemperatur / PNC Inside temperature
          signal PNC_11_Real_Time_Monitoring_ST3: start 19, 1 bit, little-endian, data-type-policy=OVERRIDE, i-signal-type=PRIMITIVE, init-value=0, base-type=boolean, transfer-property=PENDING  # PNC Real time monitoring
          signal PNC_12_Interior_Light_ST3: start 20, 1 bit, little-endian, data-type-policy=OVERRIDE, i-signal-type=PRIMITIVE, init-value=0, base-type=boolean, transfer-property=PENDING  # PNC Innenlicht / PNC Interior lights
          signal PNC_13_Living_ST3: start 21, 1 bit, little-endian, data-type-policy=OVERRIDE, i-signal-type=PRIMITIVE, init-value=0, base-type=boolean, transfer-property=PENDING  # PNC Living
          signal PNC_14_Driver_Information_ST3: start 22, 1 bit, little-endian, data-type-policy=OVERRIDE, i-signal-type=PRIMITIVE, init-value=0, base-type=boolean, transfer-property=PENDING
          signal PNC_15_FOTA_ST3: start 23, 1 bit, little-endian, data-type-policy=OVERRIDE, i-signal-type=PRIMITIVE, init-value=0, base-type=boolean, transfer-property=PENDING
          signal PNC_16_BMS_Sensor_Active_ST3: start 24, 1 bit, little-endian, data-type-policy=OVERRIDE, i-signal-type=PRIMITIVE, init-value=0, base-type=boolean, transfer-property=PENDING
          signal PNC_17_EIS_Active_ST3: start 25, 1 bit, little-endian, data-type-policy=OVERRIDE, i-signal-type=PRIMITIVE, init-value=0, base-type=boolean, transfer-property=PENDING
          signal PNC_18_HV_Charging_UI_Set_ST3: start 26, 1 bit, little-endian, data-type-policy=OVERRIDE, i-signal-type=PRIMITIVE, init-value=0, base-type=boolean, transfer-property=PENDING  # PNC 18 HV Charging Bedienung Einstellungen ST3 / PNC 18 HV Charging User Interaction settings ST3
          signal PNC_19_Afterrun_Cooling_ST3: start 27, 1 bit, little-endian, data-type-policy=OVERRIDE, i-signal-type=PRIMITIVE, init-value=0, base-type=boolean, transfer-property=PENDING  # PNC Afterrun Cooling
          signal PNC_20_Driving_ST3: start 28, 1 bit, little-endian, data-type-policy=OVERRIDE, i-signal-type=PRIMITIVE, init-value=0, base-type=boolean, transfer-property=PENDING  # PNC 20 Driving
          signal PNC_21_KeylessGo_ST3: start 29, 1 bit, little-endian, data-type-policy=OVERRIDE, i-signal-type=PRIMITIVE, init-value=0, base-type=boolean, transfer-property=PENDING
          signal PNC_22_ThermalComfort_ST3: start 30, 1 bit, little-endian, data-type-policy=OVERRIDE, i-signal-type=PRIMITIVE, init-value=0, base-type=boolean, transfer-property=PENDING
          signal PNC_23_HAD_Driving_ST3: start 31, 1 bit, little-endian, data-type-policy=OVERRIDE, i-signal-type=PRIMITIVE, init-value=0, base-type=boolean, transfer-property=PENDING
          signal PNC_24_SecondaryPowernet_ST3: start 32, 1 bit, little-endian, data-type-policy=OVERRIDE, i-signal-type=PRIMITIVE, init-value=0, base-type=boolean, transfer-property=PENDING
          signal PNC_25_Trailer_ST3: start 33, 1 bit, little-endian, data-type-policy=OVERRIDE, i-signal-type=PRIMITIVE, init-value=0, base-type=boolean, transfer-property=PENDING
          signal PNC_26_ECall_ST35: start 34, 1 bit, little-endian, data-type-policy=OVERRIDE, i-signal-type=PRIMITIVE, init-value=0, base-type=boolean, transfer-property=PENDING
          signal PNC_27_eDrive_active_ComCtrl_ST3: start 35, 1 bit, little-endian, data-type-policy=OVERRIDE, i-signal-type=PRIMITIVE, init-value=0, base-type=boolean, transfer-property=PENDING
          signal PNC_28_Charging_Components_ComCtrl_ST3: start 36, 1 bit, little-endian, data-type-policy=OVERRIDE, i-signal-type=PRIMITIVE, init-value=0, base-type=boolean, transfer-property=PENDING
      frame NM_IMU_B_ST3: id 0x1442016B, from IMU_B, frame-length=8, can-addressing-mode=EXTENDED, can-frame-rx-behavior=CAN-20, can-frame-tx-behavior=CAN-20  # Netzwerk-Management / Network Management
        nm pdu NM_IMU_B_ST3: length=8, nm-data-information=true, unused-bit-pattern=0  # STAR3 NM PDU
          signal NM_ActvWakeup: start 4, 1 bit, little-endian, data-type-policy=OVERRIDE, i-signal-type=PRIMITIVE, init-value=0, base-type=boolean, transfer-property=PENDING  # Active Wakeup Bit
          signal NM_Coord_Id: start 1, 2 bit, little-endian, data-type-policy=OVERRIDE, i-signal-type=PRIMITIVE, init-value=0, base-type=uint8, range raw 0..3, transfer-property=PENDING  # NM Coordinator ID
          signal NM_Coord_SleepRdy: start 3, 1 bit, little-endian, data-type-policy=OVERRIDE, i-signal-type=PRIMITIVE, init-value=0, base-type=boolean, transfer-property=PENDING  # NM Coordinator Sleep Ready Bit
          signal NM_PartNw_Info: start 6, 1 bit, little-endian, data-type-policy=OVERRIDE, i-signal-type=PRIMITIVE, init-value=0, base-type=boolean, transfer-property=PENDING  # Partial Network Information Bit
          signal NM_RepeatMsg_Rq: start 0, 1 bit, little-endian, data-type-policy=OVERRIDE, i-signal-type=PRIMITIVE, init-value=0, base-type=boolean, transfer-property=PENDING  # Repeat Message Request
          signal PNC_00_All_Active_ST3: start 8, 1 bit, little-endian, data-type-policy=OVERRIDE, i-signal-type=PRIMITIVE, init-value=0, base-type=boolean, transfer-property=PENDING  # PNC All Active
          signal PNC_01_HV_Charging_ST3: start 9, 1 bit, little-endian, data-type-policy=OVERRIDE, i-signal-type=PRIMITIVE, init-value=0, base-type=boolean, transfer-property=PENDING  # PNC Hochspannungsladen / PNC high voltage charging
          signal PNC_02_Recharge_Mode_HV_12V_ST3: start 10, 1 bit, little-endian, data-type-policy=OVERRIDE, i-signal-type=PRIMITIVE, init-value=0, base-type=boolean, transfer-property=PENDING  # PNC Umladen zwischen Hochspannung und 12V / PNC recharge betweeen high voltage and 12V
          signal PNC_03_Preconditioning_ST3: start 11, 1 bit, little-endian, data-type-policy=OVERRIDE, i-signal-type=PRIMITIVE, init-value=0, base-type=boolean, transfer-property=PENDING  # PNC Vorkonditionierung / PNC Preconditioning
          signal PNC_04_Telematics_Standalone_ST3: start 12, 1 bit, little-endian, data-type-policy=OVERRIDE, i-signal-type=PRIMITIVE, init-value=0, base-type=boolean, transfer-property=PENDING  # PNC Telematic standalone
          signal PNC_05_Warning_Lights_ST3: start 13, 1 bit, little-endian, data-type-policy=OVERRIDE, i-signal-type=PRIMITIVE, init-value=0, base-type=boolean, transfer-property=PENDING  # PNC Warnblinker / PNC Warning lights
          signal PNC_06_Exit_Warning_ST3: start 14, 1 bit, little-endian, data-type-policy=OVERRIDE, i-signal-type=PRIMITIVE, init-value=0, base-type=boolean, transfer-property=PENDING  # PNC Ausstiegswarnung / PNC Exit warning
          signal PNC_07_SeatComfort_ST3: start 15, 1 bit, little-endian, data-type-policy=OVERRIDE, i-signal-type=PRIMITIVE, init-value=0, base-type=boolean, transfer-property=PENDING  # PNC_07 Seat Comfort
          signal PNC_08_Telematics_Communication_ST3: start 16, 1 bit, little-endian, data-type-policy=OVERRIDE, i-signal-type=PRIMITIVE, init-value=0, base-type=boolean, transfer-property=PENDING  # PNC Telematics communication
          signal PNC_09_IDC_Standalone_ST3: start 17, 1 bit, little-endian, data-type-policy=OVERRIDE, i-signal-type=PRIMITIVE, init-value=0, base-type=boolean, transfer-property=PENDING  # PNC IDC Standalone
          signal PNC_10_Inside_Temp_ST3: start 18, 1 bit, little-endian, data-type-policy=OVERRIDE, i-signal-type=PRIMITIVE, init-value=0, base-type=boolean, transfer-property=PENDING  # PNC Innentemperatur / PNC Inside temperature
          signal PNC_11_Real_Time_Monitoring_ST3: start 19, 1 bit, little-endian, data-type-policy=OVERRIDE, i-signal-type=PRIMITIVE, init-value=0, base-type=boolean, transfer-property=PENDING  # PNC Real time monitoring
          signal PNC_12_Interior_Light_ST3: start 20, 1 bit, little-endian, data-type-policy=OVERRIDE, i-signal-type=PRIMITIVE, init-value=0, base-type=boolean, transfer-property=PENDING  # PNC Innenlicht / PNC Interior lights
          signal PNC_13_Living_ST3: start 21, 1 bit, little-endian, data-type-policy=OVERRIDE, i-signal-type=PRIMITIVE, init-value=0, base-type=boolean, transfer-property=PENDING  # PNC Living
          signal PNC_14_Driver_Information_ST3: start 22, 1 bit, little-endian, data-type-policy=OVERRIDE, i-signal-type=PRIMITIVE, init-value=0, base-type=boolean, transfer-property=PENDING
          signal PNC_15_FOTA_ST3: start 23, 1 bit, little-endian, data-type-policy=OVERRIDE, i-signal-type=PRIMITIVE, init-value=0, base-type=boolean, transfer-property=PENDING
          signal PNC_16_BMS_Sensor_Active_ST3: start 24, 1 bit, little-endian, data-type-policy=OVERRIDE, i-signal-type=PRIMITIVE, init-value=0, base-type=boolean, transfer-property=PENDING
          signal PNC_17_EIS_Active_ST3: start 25, 1 bit, little-endian, data-type-policy=OVERRIDE, i-signal-type=PRIMITIVE, init-value=0, base-type=boolean, transfer-property=PENDING
          signal PNC_18_HV_Charging_UI_Set_ST3: start 26, 1 bit, little-endian, data-type-policy=OVERRIDE, i-signal-type=PRIMITIVE, init-value=0, base-type=boolean, transfer-property=PENDING  # PNC 18 HV Charging Bedienung Einstellungen ST3 / PNC 18 HV Charging User Interaction settings ST3
          signal PNC_19_Afterrun_Cooling_ST3: start 27, 1 bit, little-endian, data-type-policy=OVERRIDE, i-signal-type=PRIMITIVE, init-value=0, base-type=boolean, transfer-property=PENDING  # PNC Afterrun Cooling
          signal PNC_20_Driving_ST3: start 28, 1 bit, little-endian, data-type-policy=OVERRIDE, i-signal-type=PRIMITIVE, init-value=0, base-type=boolean, transfer-property=PENDING  # PNC 20 Driving
          signal PNC_21_KeylessGo_ST3: start 29, 1 bit, little-endian, data-type-policy=OVERRIDE, i-signal-type=PRIMITIVE, init-value=0, base-type=boolean, transfer-property=PENDING
          signal PNC_22_ThermalComfort_ST3: start 30, 1 bit, little-endian, data-type-policy=OVERRIDE, i-signal-type=PRIMITIVE, init-value=0, base-type=boolean, transfer-property=PENDING
          signal PNC_23_HAD_Driving_ST3: start 31, 1 bit, little-endian, data-type-policy=OVERRIDE, i-signal-type=PRIMITIVE, init-value=0, base-type=boolean, transfer-property=PENDING
          signal PNC_24_SecondaryPowernet_ST3: start 32, 1 bit, little-endian, data-type-policy=OVERRIDE, i-signal-type=PRIMITIVE, init-value=0, base-type=boolean, transfer-property=PENDING
          signal PNC_25_Trailer_ST3: start 33, 1 bit, little-endian, data-type-policy=OVERRIDE, i-signal-type=PRIMITIVE, init-value=0, base-type=boolean, transfer-property=PENDING
          signal PNC_26_ECall_ST35: start 34, 1 bit, little-endian, data-type-policy=OVERRIDE, i-signal-type=PRIMITIVE, init-value=0, base-type=boolean, transfer-property=PENDING
          signal PNC_27_eDrive_active_ComCtrl_ST3: start 35, 1 bit, little-endian, data-type-policy=OVERRIDE, i-signal-type=PRIMITIVE, init-value=0, base-type=boolean, transfer-property=PENDING
          signal PNC_28_Charging_Components_ComCtrl_ST3: start 36, 1 bit, little-endian, data-type-policy=OVERRIDE, i-signal-type=PRIMITIVE, init-value=0, base-type=boolean, transfer-property=PENDING
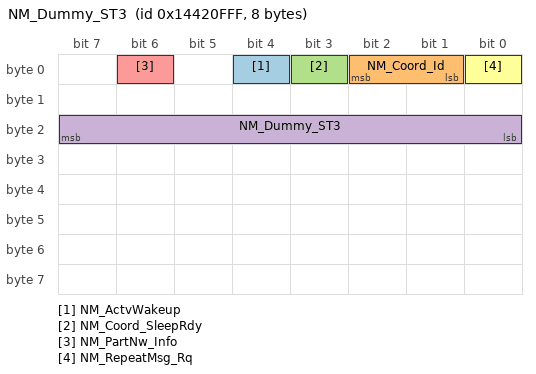
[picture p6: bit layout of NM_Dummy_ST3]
      frame NM_Dummy_ST3: id 0x14420FFF, to IMU_A IMU_B, frame-length=8, can-addressing-mode=EXTENDED, can-frame-rx-behavior=CAN-20, can-frame-tx-behavior=CAN-20, rx-identifier-range={lower-can-id=339869696, upper-can-id=339873791}  # Netzwerk-Management / Network Management
        nm pdu NM_Dummy_ST3: length=8, nm-data-information=true, unused-bit-pattern=0  # Netzwerk-Management / Network Management
          signal NM_ActvWakeup: start 4, 1 bit, little-endian, data-type-policy=OVERRIDE, i-signal-type=PRIMITIVE, init-value=0, base-type=boolean, transfer-property=PENDING  # Active Wakeup Bit
          signal NM_Coord_Id: start 1, 2 bit, little-endian, data-type-policy=OVERRIDE, i-signal-type=PRIMITIVE, init-value=0, base-type=uint8, range raw 0..3, transfer-property=PENDING  # NM Coordinator ID
          signal NM_Coord_SleepRdy: start 3, 1 bit, little-endian, data-type-policy=OVERRIDE, i-signal-type=PRIMITIVE, init-value=0, base-type=boolean, transfer-property=PENDING  # NM Coordinator Sleep Ready Bit
          signal NM_Dummy_ST3: start 16, 8 bit, little-endian, data-type-policy=OVERRIDE, i-signal-type=PRIMITIVE, init-value=0, base-type=uint8, data-constr=c08_UInt_SNA_na, transfer-property=PENDING  # Netzwerk-Management Dummy-Signal für alle NM-PDUs / Network Management dummy signal for all NM PDUs
          signal NM_PartNw_Info: start 6, 1 bit, little-endian, data-type-policy=OVERRIDE, i-signal-type=PRIMITIVE, init-value=0, base-type=boolean, transfer-property=PENDING  # Partial Network Information Bit
          signal NM_RepeatMsg_Rq: start 0, 1 bit, little-endian, data-type-policy=OVERRIDE, i-signal-type=PRIMITIVE, init-value=0, base-type=boolean, transfer-property=PENDING  # Repeat Message Request
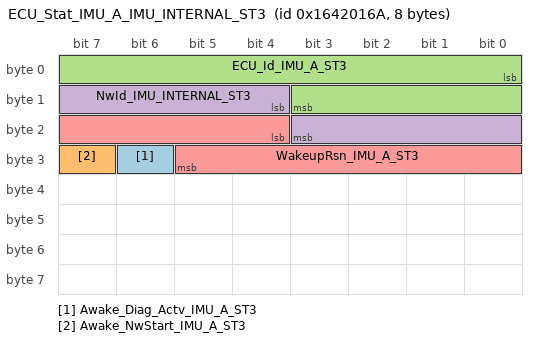
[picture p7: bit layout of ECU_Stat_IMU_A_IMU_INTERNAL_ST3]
      frame ECU_Stat_IMU_A_IMU_INTERNAL_ST3: id 0x1642016A, from IMU_A, frame-length=8, can-addressing-mode=EXTENDED, can-frame-rx-behavior=CAN-FD, can-frame-tx-behavior=CAN-FD  # ECU Status / ECU state
        pdu ECU_Stat_IMU_A_IMU_INTERNAL_ST3: length=8, transmission-mode-true-timing=cyclic-timing={time-offset=0.0, time-period=1.0}, unused-bit-pattern=0  # ECU Status / ECU state
          signal Awake_Diag_Actv_IMU_A_ST3: start 30, 1 bit, little-endian, data-type-policy=OVERRIDE, i-signal-type=PRIMITIVE, init-value=0, base-type=boolean, transfer-property=PENDING  # Wachhalten für Diagnose aktiv / Stay awake for diagnostics active
          signal Awake_NwStart_IMU_A_ST3: start 31, 1 bit, little-endian, data-type-policy=OVERRIDE, i-signal-type=PRIMITIVE, init-value=0, base-type=boolean, transfer-property=PENDING  # Wachhalten für Netzwerkstartphase / Stay awake for network startup
          signal ECU_Id_IMU_A_ST3: start 0, 12 bit, little-endian, data-type-policy=OVERRIDE, i-signal-type=PRIMITIVE, init-value=362, base-type=uint16, invalid-value=4095, compu-method=c12_0_4094_1_SNA, data-constr=c12_0_4094_1_SNA, transfer-property=PENDING  # ECU-Identifizierungsnummer / ECU identifier
          signal NwId_IMU_INTERNAL_ST3: start 12, 8 bit, little-endian, data-type-policy=OVERRIDE, i-signal-type=PRIMITIVE, init-value=47, base-type=uint8, invalid-value=255, compu-method=c08_0_254_1_SNA_255, data-constr=c08_0_254_1_SNA_255, transfer-property=PENDING  # Netzwerk-Identifizierungsnummer / Network identifier
          signal WakeupRsn_IMU_A_ST3: start 20, 10 bit, little-endian, data-type-policy=OVERRIDE, i-signal-type=PRIMITIVE, init-value=1023, base-type=uint16, invalid-value=1023, compu-method=c10_WakeupRsn_ST3, data-constr=c10_WakeupRsn_ST3, transfer-property=PENDING  # Weckgrund / Wakeup reason
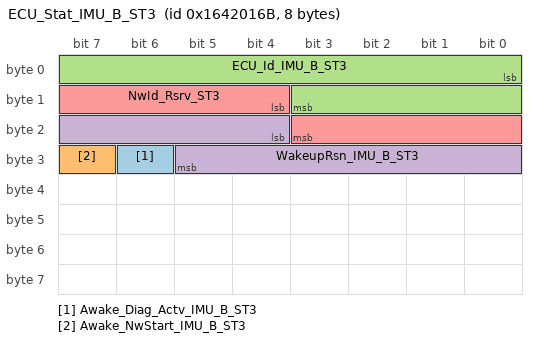
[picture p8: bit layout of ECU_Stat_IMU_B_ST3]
      frame ECU_Stat_IMU_B_ST3: id 0x1642016B, from IMU_B, to IMU_A, frame-length=8, can-addressing-mode=EXTENDED, can-frame-rx-behavior=CAN-FD, can-frame-tx-behavior=CAN-FD  # ECU Status / ECU state
        pdu ECU_Stat_IMU_B_ST3: length=8, transmission-mode-true-timing=cyclic-timing={time-offset=0.005, time-period=1.0}, unused-bit-pattern=0  # ECU Status / ECU state
          signal Awake_Diag_Actv_IMU_B_ST3: start 30, 1 bit, little-endian, data-type-policy=OVERRIDE, i-signal-type=PRIMITIVE, init-value=0, base-type=boolean, transfer-property=PENDING, to IMU_A  # Wachhalten für Diagnose aktiv / Stay awake for diagnostics active
          signal Awake_NwStart_IMU_B_ST3: start 31, 1 bit, little-endian, data-type-policy=OVERRIDE, i-signal-type=PRIMITIVE, init-value=0, base-type=boolean, transfer-property=PENDING, to IMU_A  # Wachhalten für Netzwerkstartphase / Stay awake for network startup
          signal ECU_Id_IMU_B_ST3: start 0, 12 bit, little-endian, data-type-policy=OVERRIDE, i-signal-type=PRIMITIVE, init-value=363, base-type=uint16, invalid-value=4095, compu-method=c12_0_4094_1_SNA, data-constr=c12_0_4094_1_SNA, transfer-property=PENDING, to IMU_A  # ECU-Identifizierungsnummer / ECU identifier
          signal WakeupRsn_IMU_B_ST3: start 20, 10 bit, little-endian, data-type-policy=OVERRIDE, i-signal-type=PRIMITIVE, init-value=1023, base-type=uint16, invalid-value=1023, compu-method=c10_WakeupRsn_ST3, data-constr=c10_WakeupRsn_ST3, transfer-property=PENDING, to IMU_A  # Weckgrund / Wakeup reason
          signal NwId_Rsrv_ST3: start 12, 8 bit, little-endian, data-type-policy=OVERRIDE, i-signal-type=PRIMITIVE, init-value=0, base-type=uint8, invalid-value=255, compu-method=c08_0_254_1_SNA_255, data-constr=c08_0_254_1_SNA_255, transfer-property=PENDING  # Signal to close the gap in ECU-Stat-PDUs for ECUs w/o NW-ID
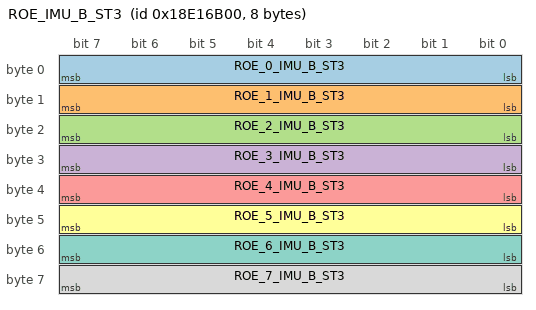
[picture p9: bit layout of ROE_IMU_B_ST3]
      frame ROE_IMU_B_ST3: id 0x18E16B00, from IMU_B, to IMU_A, frame-length=8, can-addressing-mode=EXTENDED, can-frame-rx-behavior=CAN-FD, can-frame-tx-behavior=CAN-FD  # ROE IMU B ST3
        pdu ROE_IMU_B_ST3: length=8, minimum-delay=0.2, transmission-mode-true-timing=event-controlled-timing=number-of-repetitions=0, unused-bit-pattern=0  # Ereignis-Antwort / Response on Event
          signal ROE_0_IMU_B_ST3: start 0, 8 bit, little-endian, data-type-policy=OVERRIDE, i-signal-type=PRIMITIVE, init-value=0, base-type=uint8, compu-method=c08_ROE_0, data-constr=c08_ROE_0, to IMU_A  # Ereignis-Antwort / Response on Event
          signal ROE_1_IMU_B_ST3: start 8, 8 bit, little-endian, data-type-policy=OVERRIDE, i-signal-type=PRIMITIVE, init-value=0, base-type=uint8, data-constr=c08_UInt_SNA_na, to IMU_A  # Ereignis-Antwort / Response on Event
          signal ROE_2_IMU_B_ST3: start 16, 8 bit, little-endian, data-type-policy=OVERRIDE, i-signal-type=PRIMITIVE, init-value=0, base-type=uint8, data-constr=c08_UInt_SNA_na, to IMU_A  # Ereignis-Antwort / Response on Event
          signal ROE_3_IMU_B_ST3: start 24, 8 bit, little-endian, data-type-policy=OVERRIDE, i-signal-type=PRIMITIVE, init-value=0, base-type=uint8, data-constr=c08_UInt_SNA_na, to IMU_A  # Ereignis-Antwort / Response on Event
          signal ROE_4_IMU_B_ST3: start 32, 8 bit, little-endian, data-type-policy=OVERRIDE, i-signal-type=PRIMITIVE, init-value=0, base-type=uint8, data-constr=c08_UInt_SNA_na, to IMU_A  # Ereignis-Antwort / Response on Event
          signal ROE_5_IMU_B_ST3: start 40, 8 bit, little-endian, data-type-policy=OVERRIDE, i-signal-type=PRIMITIVE, init-value=0, base-type=uint8, data-constr=c08_UInt_SNA_na, to IMU_A  # Ereignis-Antwort / Response on Event
          signal ROE_6_IMU_B_ST3: start 48, 8 bit, little-endian, data-type-policy=OVERRIDE, i-signal-type=PRIMITIVE, init-value=0, base-type=uint8, data-constr=c08_UInt_SNA_na, to IMU_A  # Ereignis-Antwort / Response on Event
          signal ROE_7_IMU_B_ST3: start 56, 8 bit, little-endian, data-type-policy=OVERRIDE, i-signal-type=PRIMITIVE, init-value=0, base-type=uint8, data-constr=c08_UInt_SNA_na, to IMU_A  # Ereignis-Antwort / Response on Event
          mapping ROE_IMU_B_ST3_7zavpp3siu6s2eitdaqxg7lwg: i-signal-group=ROE_IMU_B_ST3_7zavpp3siu6s2eitdaqxg7lwg, packing-byte-order=little-endian, transfer-property=TRIGGERED
      frame XCP_Rs_IMU_B_ST3: id 0x18E16B08, from IMU_B, frame-length=64, can-addressing-mode=EXTENDED, can-frame-rx-behavior=CAN-FD, can-frame-tx-behavior=CAN-FD
        general purpose i pdu XCP_Rs_IMU_B_ST3: category=XCP, length=64  # XCP-Anforderung / Extended calibration protocol response
      frame XCP_Rq_IMU_B_ST3: id 0x18E16B09, to IMU_B, frame-length=64, can-addressing-mode=EXTENDED, can-frame-rx-behavior=CAN-FD, can-frame-tx-behavior=CAN-FD
        general purpose i pdu XCP_Rq_IMU_B_ST3: category=XCP, length=64  # XCP-Anforderung / Extended calibration protocol request
      frame Develop_Rs_IMU_B_ST3: id 0x18E16B40, from IMU_B, frame-length=64, can-addressing-mode=EXTENDED, can-frame-rx-behavior=CAN-FD, can-frame-tx-behavior=CAN-FD  # Development Response
        pdu Develop_Rs_IMU_B_ST3: length=64, minimum-delay=0.02, transmission-mode-true-timing=event-controlled-timing=number-of-repetitions=0, unused-bit-pattern=0  # Development Response
          signal Develop_Rs_IMU_B_01_ST3: start 0, 8 bit, little-endian, data-type-policy=OVERRIDE, i-signal-type=PRIMITIVE, init-value=0, base-type=uint8, data-constr=c08_UInt_SNA_na  # Development Response
          signal Develop_Rs_IMU_B_02_ST3: start 8, 8 bit, little-endian, data-type-policy=OVERRIDE, i-signal-type=PRIMITIVE, init-value=0, base-type=uint8, data-constr=c08_UInt_SNA_na  # Development Response
          signal Develop_Rs_IMU_B_03_ST3: start 16, 8 bit, little-endian, data-type-policy=OVERRIDE, i-signal-type=PRIMITIVE, init-value=0, base-type=uint8, data-constr=c08_UInt_SNA_na  # Development Response
          signal Develop_Rs_IMU_B_04_ST3: start 24, 8 bit, little-endian, data-type-policy=OVERRIDE, i-signal-type=PRIMITIVE, init-value=0, base-type=uint8, data-constr=c08_UInt_SNA_na  # Development Response
          signal Develop_Rs_IMU_B_05_ST3: start 32, 8 bit, little-endian, data-type-policy=OVERRIDE, i-signal-type=PRIMITIVE, init-value=0, base-type=uint8, data-constr=c08_UInt_SNA_na  # Development Response
          signal Develop_Rs_IMU_B_06_ST3: start 40, 8 bit, little-endian, data-type-policy=OVERRIDE, i-signal-type=PRIMITIVE, init-value=0, base-type=uint8, data-constr=c08_UInt_SNA_na  # Development Response
          signal Develop_Rs_IMU_B_07_ST3: start 48, 8 bit, little-endian, data-type-policy=OVERRIDE, i-signal-type=PRIMITIVE, init-value=0, base-type=uint8, data-constr=c08_UInt_SNA_na  # Development Response
          signal Develop_Rs_IMU_B_08_ST3: start 56, 8 bit, little-endian, data-type-policy=OVERRIDE, i-signal-type=PRIMITIVE, init-value=0, base-type=uint8, data-constr=c08_UInt_SNA_na  # Development Response
          signal Develop_Rs_IMU_B_09_ST3: start 64, 8 bit, little-endian, data-type-policy=OVERRIDE, i-signal-type=PRIMITIVE, init-value=0, base-type=uint8, data-constr=c08_UInt_SNA_na  # Development Response
          signal Develop_Rs_IMU_B_10_ST3: start 72, 8 bit, little-endian, data-type-policy=OVERRIDE, i-signal-type=PRIMITIVE, init-value=0, base-type=uint8, data-constr=c08_UInt_SNA_na  # Development Response
          signal Develop_Rs_IMU_B_11_ST3: start 80, 8 bit, little-endian, data-type-policy=OVERRIDE, i-signal-type=PRIMITIVE, init-value=0, base-type=uint8, data-constr=c08_UInt_SNA_na  # Development Response
          signal Develop_Rs_IMU_B_12_ST3: start 88, 8 bit, little-endian, data-type-policy=OVERRIDE, i-signal-type=PRIMITIVE, init-value=0, base-type=uint8, data-constr=c08_UInt_SNA_na  # Development Response
          signal Develop_Rs_IMU_B_13_ST3: start 96, 8 bit, little-endian, data-type-policy=OVERRIDE, i-signal-type=PRIMITIVE, init-value=0, base-type=uint8, data-constr=c08_UInt_SNA_na  # Development Response
          signal Develop_Rs_IMU_B_14_ST3: start 104, 8 bit, little-endian, data-type-policy=OVERRIDE, i-signal-type=PRIMITIVE, init-value=0, base-type=uint8, data-constr=c08_UInt_SNA_na  # Development Response
          signal Develop_Rs_IMU_B_15_ST3: start 112, 8 bit, little-endian, data-type-policy=OVERRIDE, i-signal-type=PRIMITIVE, init-value=0, base-type=uint8, data-constr=c08_UInt_SNA_na  # Development Response
          signal Develop_Rs_IMU_B_16_ST3: start 120, 8 bit, little-endian, data-type-policy=OVERRIDE, i-signal-type=PRIMITIVE, init-value=0, base-type=uint8, data-constr=c08_UInt_SNA_na  # Development Response
          signal Develop_Rs_IMU_B_17_ST3: start 128, 8 bit, little-endian, data-type-policy=OVERRIDE, i-signal-type=PRIMITIVE, init-value=0, base-type=uint8, data-constr=c08_UInt_SNA_na  # Development Response
          signal Develop_Rs_IMU_B_18_ST3: start 136, 8 bit, little-endian, data-type-policy=OVERRIDE, i-signal-type=PRIMITIVE, init-value=0, base-type=uint8, data-constr=c08_UInt_SNA_na  # Development Response
          signal Develop_Rs_IMU_B_19_ST3: start 144, 8 bit, little-endian, data-type-policy=OVERRIDE, i-signal-type=PRIMITIVE, init-value=0, base-type=uint8, data-constr=c08_UInt_SNA_na  # Development Response
          signal Develop_Rs_IMU_B_20_ST3: start 152, 8 bit, little-endian, data-type-policy=OVERRIDE, i-signal-type=PRIMITIVE, init-value=0, base-type=uint8, data-constr=c08_UInt_SNA_na  # Development Response
          signal Develop_Rs_IMU_B_21_ST3: start 160, 8 bit, little-endian, data-type-policy=OVERRIDE, i-signal-type=PRIMITIVE, init-value=0, base-type=uint8, data-constr=c08_UInt_SNA_na  # Development Response
          signal Develop_Rs_IMU_B_22_ST3: start 168, 8 bit, little-endian, data-type-policy=OVERRIDE, i-signal-type=PRIMITIVE, init-value=0, base-type=uint8, data-constr=c08_UInt_SNA_na  # Development Response
          signal Develop_Rs_IMU_B_23_ST3: start 176, 8 bit, little-endian, data-type-policy=OVERRIDE, i-signal-type=PRIMITIVE, init-value=0, base-type=uint8, data-constr=c08_UInt_SNA_na  # Development Response
          signal Develop_Rs_IMU_B_24_ST3: start 184, 8 bit, little-endian, data-type-policy=OVERRIDE, i-signal-type=PRIMITIVE, init-value=0, base-type=uint8, data-constr=c08_UInt_SNA_na  # Development Response
          signal Develop_Rs_IMU_B_25_ST3: start 192, 8 bit, little-endian, data-type-policy=OVERRIDE, i-signal-type=PRIMITIVE, init-value=0, base-type=uint8, data-constr=c08_UInt_SNA_na  # Development Response
          signal Develop_Rs_IMU_B_26_ST3: start 200, 8 bit, little-endian, data-type-policy=OVERRIDE, i-signal-type=PRIMITIVE, init-value=0, base-type=uint8, data-constr=c08_UInt_SNA_na  # Development Response
          signal Develop_Rs_IMU_B_27_ST3: start 208, 8 bit, little-endian, data-type-policy=OVERRIDE, i-signal-type=PRIMITIVE, init-value=0, base-type=uint8, data-constr=c08_UInt_SNA_na  # Development Response
          signal Develop_Rs_IMU_B_28_ST3: start 216, 8 bit, little-endian, data-type-policy=OVERRIDE, i-signal-type=PRIMITIVE, init-value=0, base-type=uint8, data-constr=c08_UInt_SNA_na  # Development Response
          signal Develop_Rs_IMU_B_29_ST3: start 224, 8 bit, little-endian, data-type-policy=OVERRIDE, i-signal-type=PRIMITIVE, init-value=0, base-type=uint8, data-constr=c08_UInt_SNA_na  # Development Response
          signal Develop_Rs_IMU_B_30_ST3: start 232, 8 bit, little-endian, data-type-policy=OVERRIDE, i-signal-type=PRIMITIVE, init-value=0, base-type=uint8, data-constr=c08_UInt_SNA_na  # Development Response
          signal Develop_Rs_IMU_B_31_ST3: start 240, 8 bit, little-endian, data-type-policy=OVERRIDE, i-signal-type=PRIMITIVE, init-value=0, base-type=uint8, data-constr=c08_UInt_SNA_na  # Development Response
          signal Develop_Rs_IMU_B_32_ST3: start 248, 8 bit, little-endian, data-type-policy=OVERRIDE, i-signal-type=PRIMITIVE, init-value=0, base-type=uint8, data-constr=c08_UInt_SNA_na  # Development Response
          signal Develop_Rs_IMU_B_33_ST3: start 256, 8 bit, little-endian, data-type-policy=OVERRIDE, i-signal-type=PRIMITIVE, init-value=0, base-type=uint8, data-constr=c08_UInt_SNA_na  # Development Response
          signal Develop_Rs_IMU_B_34_ST3: start 264, 8 bit, little-endian, data-type-policy=OVERRIDE, i-signal-type=PRIMITIVE, init-value=0, base-type=uint8, data-constr=c08_UInt_SNA_na  # Development Response
          signal Develop_Rs_IMU_B_35_ST3: start 272, 8 bit, little-endian, data-type-policy=OVERRIDE, i-signal-type=PRIMITIVE, init-value=0, base-type=uint8, data-constr=c08_UInt_SNA_na  # Development Response
          signal Develop_Rs_IMU_B_36_ST3: start 280, 8 bit, little-endian, data-type-policy=OVERRIDE, i-signal-type=PRIMITIVE, init-value=0, base-type=uint8, data-constr=c08_UInt_SNA_na  # Development Response
          signal Develop_Rs_IMU_B_37_ST3: start 288, 8 bit, little-endian, data-type-policy=OVERRIDE, i-signal-type=PRIMITIVE, init-value=0, base-type=uint8, data-constr=c08_UInt_SNA_na  # Development Response
          signal Develop_Rs_IMU_B_38_ST3: start 296, 8 bit, little-endian, data-type-policy=OVERRIDE, i-signal-type=PRIMITIVE, init-value=0, base-type=uint8, data-constr=c08_UInt_SNA_na  # Development Response
          signal Develop_Rs_IMU_B_39_ST3: start 304, 8 bit, little-endian, data-type-policy=OVERRIDE, i-signal-type=PRIMITIVE, init-value=0, base-type=uint8, data-constr=c08_UInt_SNA_na  # Development Response
          signal Develop_Rs_IMU_B_40_ST3: start 312, 8 bit, little-endian, data-type-policy=OVERRIDE, i-signal-type=PRIMITIVE, init-value=0, base-type=uint8, data-constr=c08_UInt_SNA_na  # Development Response
          signal Develop_Rs_IMU_B_41_ST3: start 320, 8 bit, little-endian, data-type-policy=OVERRIDE, i-signal-type=PRIMITIVE, init-value=0, base-type=uint8, data-constr=c08_UInt_SNA_na  # Development Response
          signal Develop_Rs_IMU_B_42_ST3: start 328, 8 bit, little-endian, data-type-policy=OVERRIDE, i-signal-type=PRIMITIVE, init-value=0, base-type=uint8, data-constr=c08_UInt_SNA_na  # Development Response
          signal Develop_Rs_IMU_B_43_ST3: start 336, 8 bit, little-endian, data-type-policy=OVERRIDE, i-signal-type=PRIMITIVE, init-value=0, base-type=uint8, data-constr=c08_UInt_SNA_na  # Development Response
          signal Develop_Rs_IMU_B_44_ST3: start 344, 8 bit, little-endian, data-type-policy=OVERRIDE, i-signal-type=PRIMITIVE, init-value=0, base-type=uint8, data-constr=c08_UInt_SNA_na  # Development Response
          signal Develop_Rs_IMU_B_45_ST3: start 352, 8 bit, little-endian, data-type-policy=OVERRIDE, i-signal-type=PRIMITIVE, init-value=0, base-type=uint8, data-constr=c08_UInt_SNA_na  # Development Response
          signal Develop_Rs_IMU_B_46_ST3: start 360, 8 bit, little-endian, data-type-policy=OVERRIDE, i-signal-type=PRIMITIVE, init-value=0, base-type=uint8, data-constr=c08_UInt_SNA_na  # Development Response
          signal Develop_Rs_IMU_B_47_ST3: start 368, 8 bit, little-endian, data-type-policy=OVERRIDE, i-signal-type=PRIMITIVE, init-value=0, base-type=uint8, data-constr=c08_UInt_SNA_na  # Development Response
          signal Develop_Rs_IMU_B_48_ST3: start 376, 8 bit, little-endian, data-type-policy=OVERRIDE, i-signal-type=PRIMITIVE, init-value=0, base-type=uint8, data-constr=c08_UInt_SNA_na  # Development Response
          signal Develop_Rs_IMU_B_49_ST3: start 384, 8 bit, little-endian, data-type-policy=OVERRIDE, i-signal-type=PRIMITIVE, init-value=0, base-type=uint8, data-constr=c08_UInt_SNA_na  # Development Response
          signal Develop_Rs_IMU_B_50_ST3: start 392, 8 bit, little-endian, data-type-policy=OVERRIDE, i-signal-type=PRIMITIVE, init-value=0, base-type=uint8, data-constr=c08_UInt_SNA_na  # Development Response
          signal Develop_Rs_IMU_B_51_ST3: start 400, 8 bit, little-endian, data-type-policy=OVERRIDE, i-signal-type=PRIMITIVE, init-value=0, base-type=uint8, data-constr=c08_UInt_SNA_na  # Development Response
          signal Develop_Rs_IMU_B_52_ST3: start 408, 8 bit, little-endian, data-type-policy=OVERRIDE, i-signal-type=PRIMITIVE, init-value=0, base-type=uint8, data-constr=c08_UInt_SNA_na  # Development Response
          signal Develop_Rs_IMU_B_53_ST3: start 416, 8 bit, little-endian, data-type-policy=OVERRIDE, i-signal-type=PRIMITIVE, init-value=0, base-type=uint8, data-constr=c08_UInt_SNA_na  # Development Response
          signal Develop_Rs_IMU_B_54_ST3: start 424, 8 bit, little-endian, data-type-policy=OVERRIDE, i-signal-type=PRIMITIVE, init-value=0, base-type=uint8, data-constr=c08_UInt_SNA_na  # Development Response
          signal Develop_Rs_IMU_B_55_ST3: start 432, 8 bit, little-endian, data-type-policy=OVERRIDE, i-signal-type=PRIMITIVE, init-value=0, base-type=uint8, data-constr=c08_UInt_SNA_na  # Development Response
          signal Develop_Rs_IMU_B_56_ST3: start 440, 8 bit, little-endian, data-type-policy=OVERRIDE, i-signal-type=PRIMITIVE, init-value=0, base-type=uint8, data-constr=c08_UInt_SNA_na  # Development Response
          signal Develop_Rs_IMU_B_57_ST3: start 448, 8 bit, little-endian, data-type-policy=OVERRIDE, i-signal-type=PRIMITIVE, init-value=0, base-type=uint8, data-constr=c08_UInt_SNA_na  # Development Response
          signal Develop_Rs_IMU_B_58_ST3: start 456, 8 bit, little-endian, data-type-policy=OVERRIDE, i-signal-type=PRIMITIVE, init-value=0, base-type=uint8, data-constr=c08_UInt_SNA_na  # Development Response
          signal Develop_Rs_IMU_B_59_ST3: start 464, 8 bit, little-endian, data-type-policy=OVERRIDE, i-signal-type=PRIMITIVE, init-value=0, base-type=uint8, data-constr=c08_UInt_SNA_na  # Development Response
          signal Develop_Rs_IMU_B_60_ST3: start 472, 8 bit, little-endian, data-type-policy=OVERRIDE, i-signal-type=PRIMITIVE, init-value=0, base-type=uint8, data-constr=c08_UInt_SNA_na  # Development Response
          signal Develop_Rs_IMU_B_61_ST3: start 480, 8 bit, little-endian, data-type-policy=OVERRIDE, i-signal-type=PRIMITIVE, init-value=0, base-type=uint8, data-constr=c08_UInt_SNA_na  # Development Response
          signal Develop_Rs_IMU_B_62_ST3: start 488, 8 bit, little-endian, data-type-policy=OVERRIDE, i-signal-type=PRIMITIVE, init-value=0, base-type=uint8, data-constr=c08_UInt_SNA_na  # Development Response
          signal Develop_Rs_IMU_B_63_ST3: start 496, 8 bit, little-endian, data-type-policy=OVERRIDE, i-signal-type=PRIMITIVE, init-value=0, base-type=uint8, data-constr=c08_UInt_SNA_na  # Development Response
          signal Develop_Rs_IMU_B_64_ST3: start 504, 8 bit, little-endian, data-type-policy=OVERRIDE, i-signal-type=PRIMITIVE, init-value=0, base-type=uint8, data-constr=c08_UInt_SNA_na  # Development Response
          mapping Develop_Rs_IMU_B_ST3_6w339n32g20u8dfzm3fvalwqe: i-signal-group=Develop_Rs_IMU_B_ST3_6w339n32g20u8dfzm3fvalwqe, packing-byte-order=little-endian, transfer-property=TRIGGERED
      frame Develop_Rq_IMU_B_ST3: id 0x18E16B41, to IMU_B, frame-length=64, can-addressing-mode=EXTENDED, can-frame-rx-behavior=CAN-FD, can-frame-tx-behavior=CAN-FD  # Development Request
        pdu Develop_Rq_IMU_B_ST3: length=64, minimum-delay=0.02, transmission-mode-true-timing=event-controlled-timing=number-of-repetitions=0, unused-bit-pattern=0  # Development Request
          signal Develop_Rq_IMU_B_01_ST3: start 0, 8 bit, little-endian, data-type-policy=OVERRIDE, i-signal-type=PRIMITIVE, init-value=0, base-type=uint8, data-constr=c08_UInt_SNA_na, to IMU_B  # Development Request
          signal Develop_Rq_IMU_B_02_ST3: start 8, 8 bit, little-endian, data-type-policy=OVERRIDE, i-signal-type=PRIMITIVE, init-value=0, base-type=uint8, data-constr=c08_UInt_SNA_na, to IMU_B  # Development Request
          signal Develop_Rq_IMU_B_03_ST3: start 16, 8 bit, little-endian, data-type-policy=OVERRIDE, i-signal-type=PRIMITIVE, init-value=0, base-type=uint8, data-constr=c08_UInt_SNA_na, to IMU_B  # Development Request
          signal Develop_Rq_IMU_B_04_ST3: start 24, 8 bit, little-endian, data-type-policy=OVERRIDE, i-signal-type=PRIMITIVE, init-value=0, base-type=uint8, data-constr=c08_UInt_SNA_na, to IMU_B  # Development Request
          signal Develop_Rq_IMU_B_05_ST3: start 32, 8 bit, little-endian, data-type-policy=OVERRIDE, i-signal-type=PRIMITIVE, init-value=0, base-type=uint8, data-constr=c08_UInt_SNA_na, to IMU_B  # Development Request
          signal Develop_Rq_IMU_B_06_ST3: start 40, 8 bit, little-endian, data-type-policy=OVERRIDE, i-signal-type=PRIMITIVE, init-value=0, base-type=uint8, data-constr=c08_UInt_SNA_na, to IMU_B  # Development Request
          signal Develop_Rq_IMU_B_07_ST3: start 48, 8 bit, little-endian, data-type-policy=OVERRIDE, i-signal-type=PRIMITIVE, init-value=0, base-type=uint8, data-constr=c08_UInt_SNA_na, to IMU_B  # Development Request
          signal Develop_Rq_IMU_B_08_ST3: start 56, 8 bit, little-endian, data-type-policy=OVERRIDE, i-signal-type=PRIMITIVE, init-value=0, base-type=uint8, data-constr=c08_UInt_SNA_na, to IMU_B  # Development Request
          signal Develop_Rq_IMU_B_09_ST3: start 64, 8 bit, little-endian, data-type-policy=OVERRIDE, i-signal-type=PRIMITIVE, init-value=0, base-type=uint8, data-constr=c08_UInt_SNA_na, to IMU_B  # Development Request
          signal Develop_Rq_IMU_B_10_ST3: start 72, 8 bit, little-endian, data-type-policy=OVERRIDE, i-signal-type=PRIMITIVE, init-value=0, base-type=uint8, data-constr=c08_UInt_SNA_na, to IMU_B  # Development Request
          signal Develop_Rq_IMU_B_11_ST3: start 80, 8 bit, little-endian, data-type-policy=OVERRIDE, i-signal-type=PRIMITIVE, init-value=0, base-type=uint8, data-constr=c08_UInt_SNA_na, to IMU_B  # Development Request
          signal Develop_Rq_IMU_B_12_ST3: start 88, 8 bit, little-endian, data-type-policy=OVERRIDE, i-signal-type=PRIMITIVE, init-value=0, base-type=uint8, data-constr=c08_UInt_SNA_na, to IMU_B  # Development Request
          signal Develop_Rq_IMU_B_13_ST3: start 96, 8 bit, little-endian, data-type-policy=OVERRIDE, i-signal-type=PRIMITIVE, init-value=0, base-type=uint8, data-constr=c08_UInt_SNA_na, to IMU_B  # Development Request
          signal Develop_Rq_IMU_B_14_ST3: start 104, 8 bit, little-endian, data-type-policy=OVERRIDE, i-signal-type=PRIMITIVE, init-value=0, base-type=uint8, data-constr=c08_UInt_SNA_na, to IMU_B  # Development Request
          signal Develop_Rq_IMU_B_15_ST3: start 112, 8 bit, little-endian, data-type-policy=OVERRIDE, i-signal-type=PRIMITIVE, init-value=0, base-type=uint8, data-constr=c08_UInt_SNA_na, to IMU_B  # Development Request
          signal Develop_Rq_IMU_B_16_ST3: start 120, 8 bit, little-endian, data-type-policy=OVERRIDE, i-signal-type=PRIMITIVE, init-value=0, base-type=uint8, data-constr=c08_UInt_SNA_na, to IMU_B  # Development Request
          signal Develop_Rq_IMU_B_17_ST3: start 128, 8 bit, little-endian, data-type-policy=OVERRIDE, i-signal-type=PRIMITIVE, init-value=0, base-type=uint8, data-constr=c08_UInt_SNA_na, to IMU_B  # Development Request
          signal Develop_Rq_IMU_B_18_ST3: start 136, 8 bit, little-endian, data-type-policy=OVERRIDE, i-signal-type=PRIMITIVE, init-value=0, base-type=uint8, data-constr=c08_UInt_SNA_na, to IMU_B  # Development Request
          signal Develop_Rq_IMU_B_19_ST3: start 144, 8 bit, little-endian, data-type-policy=OVERRIDE, i-signal-type=PRIMITIVE, init-value=0, base-type=uint8, data-constr=c08_UInt_SNA_na, to IMU_B  # Development Request
          signal Develop_Rq_IMU_B_20_ST3: start 152, 8 bit, little-endian, data-type-policy=OVERRIDE, i-signal-type=PRIMITIVE, init-value=0, base-type=uint8, data-constr=c08_UInt_SNA_na, to IMU_B  # Development Request
          signal Develop_Rq_IMU_B_21_ST3: start 160, 8 bit, little-endian, data-type-policy=OVERRIDE, i-signal-type=PRIMITIVE, init-value=0, base-type=uint8, data-constr=c08_UInt_SNA_na, to IMU_B  # Development Request
          signal Develop_Rq_IMU_B_22_ST3: start 168, 8 bit, little-endian, data-type-policy=OVERRIDE, i-signal-type=PRIMITIVE, init-value=0, base-type=uint8, data-constr=c08_UInt_SNA_na, to IMU_B  # Development Request
          signal Develop_Rq_IMU_B_23_ST3: start 176, 8 bit, little-endian, data-type-policy=OVERRIDE, i-signal-type=PRIMITIVE, init-value=0, base-type=uint8, data-constr=c08_UInt_SNA_na, to IMU_B  # Development Request
          signal Develop_Rq_IMU_B_24_ST3: start 184, 8 bit, little-endian, data-type-policy=OVERRIDE, i-signal-type=PRIMITIVE, init-value=0, base-type=uint8, data-constr=c08_UInt_SNA_na, to IMU_B  # Development Request
          signal Develop_Rq_IMU_B_25_ST3: start 192, 8 bit, little-endian, data-type-policy=OVERRIDE, i-signal-type=PRIMITIVE, init-value=0, base-type=uint8, data-constr=c08_UInt_SNA_na, to IMU_B  # Development Request
          signal Develop_Rq_IMU_B_26_ST3: start 200, 8 bit, little-endian, data-type-policy=OVERRIDE, i-signal-type=PRIMITIVE, init-value=0, base-type=uint8, data-constr=c08_UInt_SNA_na, to IMU_B  # Development Request
          signal Develop_Rq_IMU_B_27_ST3: start 208, 8 bit, little-endian, data-type-policy=OVERRIDE, i-signal-type=PRIMITIVE, init-value=0, base-type=uint8, data-constr=c08_UInt_SNA_na, to IMU_B  # Development Request
          signal Develop_Rq_IMU_B_28_ST3: start 216, 8 bit, little-endian, data-type-policy=OVERRIDE, i-signal-type=PRIMITIVE, init-value=0, base-type=uint8, data-constr=c08_UInt_SNA_na, to IMU_B  # Development Request
          signal Develop_Rq_IMU_B_29_ST3: start 224, 8 bit, little-endian, data-type-policy=OVERRIDE, i-signal-type=PRIMITIVE, init-value=0, base-type=uint8, data-constr=c08_UInt_SNA_na, to IMU_B  # Development Request
          signal Develop_Rq_IMU_B_30_ST3: start 232, 8 bit, little-endian, data-type-policy=OVERRIDE, i-signal-type=PRIMITIVE, init-value=0, base-type=uint8, data-constr=c08_UInt_SNA_na, to IMU_B  # Development Request
          signal Develop_Rq_IMU_B_31_ST3: start 240, 8 bit, little-endian, data-type-policy=OVERRIDE, i-signal-type=PRIMITIVE, init-value=0, base-type=uint8, data-constr=c08_UInt_SNA_na, to IMU_B  # Development Request
          signal Develop_Rq_IMU_B_32_ST3: start 248, 8 bit, little-endian, data-type-policy=OVERRIDE, i-signal-type=PRIMITIVE, init-value=0, base-type=uint8, data-constr=c08_UInt_SNA_na, to IMU_B  # Development Request
          signal Develop_Rq_IMU_B_33_ST3: start 256, 8 bit, little-endian, data-type-policy=OVERRIDE, i-signal-type=PRIMITIVE, init-value=0, base-type=uint8, data-constr=c08_UInt_SNA_na, to IMU_B  # Development Request
          signal Develop_Rq_IMU_B_34_ST3: start 264, 8 bit, little-endian, data-type-policy=OVERRIDE, i-signal-type=PRIMITIVE, init-value=0, base-type=uint8, data-constr=c08_UInt_SNA_na, to IMU_B  # Development Request
          signal Develop_Rq_IMU_B_35_ST3: start 272, 8 bit, little-endian, data-type-policy=OVERRIDE, i-signal-type=PRIMITIVE, init-value=0, base-type=uint8, data-constr=c08_UInt_SNA_na, to IMU_B  # Development Request
          signal Develop_Rq_IMU_B_36_ST3: start 280, 8 bit, little-endian, data-type-policy=OVERRIDE, i-signal-type=PRIMITIVE, init-value=0, base-type=uint8, data-constr=c08_UInt_SNA_na, to IMU_B  # Development Request
          signal Develop_Rq_IMU_B_37_ST3: start 288, 8 bit, little-endian, data-type-policy=OVERRIDE, i-signal-type=PRIMITIVE, init-value=0, base-type=uint8, data-constr=c08_UInt_SNA_na, to IMU_B  # Development Request
          signal Develop_Rq_IMU_B_38_ST3: start 296, 8 bit, little-endian, data-type-policy=OVERRIDE, i-signal-type=PRIMITIVE, init-value=0, base-type=uint8, data-constr=c08_UInt_SNA_na, to IMU_B  # Development Request
          signal Develop_Rq_IMU_B_39_ST3: start 304, 8 bit, little-endian, data-type-policy=OVERRIDE, i-signal-type=PRIMITIVE, init-value=0, base-type=uint8, data-constr=c08_UInt_SNA_na, to IMU_B  # Development Request
          signal Develop_Rq_IMU_B_40_ST3: start 312, 8 bit, little-endian, data-type-policy=OVERRIDE, i-signal-type=PRIMITIVE, init-value=0, base-type=uint8, data-constr=c08_UInt_SNA_na, to IMU_B  # Development Request
          signal Develop_Rq_IMU_B_41_ST3: start 320, 8 bit, little-endian, data-type-policy=OVERRIDE, i-signal-type=PRIMITIVE, init-value=0, base-type=uint8, data-constr=c08_UInt_SNA_na, to IMU_B  # Development Request
          signal Develop_Rq_IMU_B_42_ST3: start 328, 8 bit, little-endian, data-type-policy=OVERRIDE, i-signal-type=PRIMITIVE, init-value=0, base-type=uint8, data-constr=c08_UInt_SNA_na, to IMU_B  # Development Request
          signal Develop_Rq_IMU_B_43_ST3: start 336, 8 bit, little-endian, data-type-policy=OVERRIDE, i-signal-type=PRIMITIVE, init-value=0, base-type=uint8, data-constr=c08_UInt_SNA_na, to IMU_B  # Development Request
          signal Develop_Rq_IMU_B_44_ST3: start 344, 8 bit, little-endian, data-type-policy=OVERRIDE, i-signal-type=PRIMITIVE, init-value=0, base-type=uint8, data-constr=c08_UInt_SNA_na, to IMU_B  # Development Request
          signal Develop_Rq_IMU_B_45_ST3: start 352, 8 bit, little-endian, data-type-policy=OVERRIDE, i-signal-type=PRIMITIVE, init-value=0, base-type=uint8, data-constr=c08_UInt_SNA_na, to IMU_B  # Development Request
          signal Develop_Rq_IMU_B_46_ST3: start 360, 8 bit, little-endian, data-type-policy=OVERRIDE, i-signal-type=PRIMITIVE, init-value=0, base-type=uint8, data-constr=c08_UInt_SNA_na, to IMU_B  # Development Request
          signal Develop_Rq_IMU_B_47_ST3: start 368, 8 bit, little-endian, data-type-policy=OVERRIDE, i-signal-type=PRIMITIVE, init-value=0, base-type=uint8, data-constr=c08_UInt_SNA_na, to IMU_B  # Development Request
          signal Develop_Rq_IMU_B_48_ST3: start 376, 8 bit, little-endian, data-type-policy=OVERRIDE, i-signal-type=PRIMITIVE, init-value=0, base-type=uint8, data-constr=c08_UInt_SNA_na, to IMU_B  # Development Request
          signal Develop_Rq_IMU_B_49_ST3: start 384, 8 bit, little-endian, data-type-policy=OVERRIDE, i-signal-type=PRIMITIVE, init-value=0, base-type=uint8, data-constr=c08_UInt_SNA_na, to IMU_B  # Development Request
          signal Develop_Rq_IMU_B_50_ST3: start 392, 8 bit, little-endian, data-type-policy=OVERRIDE, i-signal-type=PRIMITIVE, init-value=0, base-type=uint8, data-constr=c08_UInt_SNA_na, to IMU_B  # Development Request
          signal Develop_Rq_IMU_B_51_ST3: start 400, 8 bit, little-endian, data-type-policy=OVERRIDE, i-signal-type=PRIMITIVE, init-value=0, base-type=uint8, data-constr=c08_UInt_SNA_na, to IMU_B  # Development Request
          signal Develop_Rq_IMU_B_52_ST3: start 408, 8 bit, little-endian, data-type-policy=OVERRIDE, i-signal-type=PRIMITIVE, init-value=0, base-type=uint8, data-constr=c08_UInt_SNA_na, to IMU_B  # Development Request
          signal Develop_Rq_IMU_B_53_ST3: start 416, 8 bit, little-endian, data-type-policy=OVERRIDE, i-signal-type=PRIMITIVE, init-value=0, base-type=uint8, data-constr=c08_UInt_SNA_na, to IMU_B  # Development Request
          signal Develop_Rq_IMU_B_54_ST3: start 424, 8 bit, little-endian, data-type-policy=OVERRIDE, i-signal-type=PRIMITIVE, init-value=0, base-type=uint8, data-constr=c08_UInt_SNA_na, to IMU_B  # Development Request
          signal Develop_Rq_IMU_B_55_ST3: start 432, 8 bit, little-endian, data-type-policy=OVERRIDE, i-signal-type=PRIMITIVE, init-value=0, base-type=uint8, data-constr=c08_UInt_SNA_na, to IMU_B  # Development Request
          signal Develop_Rq_IMU_B_56_ST3: start 440, 8 bit, little-endian, data-type-policy=OVERRIDE, i-signal-type=PRIMITIVE, init-value=0, base-type=uint8, data-constr=c08_UInt_SNA_na, to IMU_B  # Development Request
          signal Develop_Rq_IMU_B_57_ST3: start 448, 8 bit, little-endian, data-type-policy=OVERRIDE, i-signal-type=PRIMITIVE, init-value=0, base-type=uint8, data-constr=c08_UInt_SNA_na, to IMU_B  # Development Request
          signal Develop_Rq_IMU_B_58_ST3: start 456, 8 bit, little-endian, data-type-policy=OVERRIDE, i-signal-type=PRIMITIVE, init-value=0, base-type=uint8, data-constr=c08_UInt_SNA_na, to IMU_B  # Development Request
          signal Develop_Rq_IMU_B_59_ST3: start 464, 8 bit, little-endian, data-type-policy=OVERRIDE, i-signal-type=PRIMITIVE, init-value=0, base-type=uint8, data-constr=c08_UInt_SNA_na, to IMU_B  # Development Request
          signal Develop_Rq_IMU_B_60_ST3: start 472, 8 bit, little-endian, data-type-policy=OVERRIDE, i-signal-type=PRIMITIVE, init-value=0, base-type=uint8, data-constr=c08_UInt_SNA_na, to IMU_B  # Development Request
          signal Develop_Rq_IMU_B_61_ST3: start 480, 8 bit, little-endian, data-type-policy=OVERRIDE, i-signal-type=PRIMITIVE, init-value=0, base-type=uint8, data-constr=c08_UInt_SNA_na, to IMU_B  # Development Request
          signal Develop_Rq_IMU_B_62_ST3: start 488, 8 bit, little-endian, data-type-policy=OVERRIDE, i-signal-type=PRIMITIVE, init-value=0, base-type=uint8, data-constr=c08_UInt_SNA_na, to IMU_B  # Development Request
          signal Develop_Rq_IMU_B_63_ST3: start 496, 8 bit, little-endian, data-type-policy=OVERRIDE, i-signal-type=PRIMITIVE, init-value=0, base-type=uint8, data-constr=c08_UInt_SNA_na, to IMU_B  # Development Request
          signal Develop_Rq_IMU_B_64_ST3: start 504, 8 bit, little-endian, data-type-policy=OVERRIDE, i-signal-type=PRIMITIVE, init-value=0, base-type=uint8, data-constr=c08_UInt_SNA_na, to IMU_B  # Development Request
          mapping Develop_Rq_IMU_B_ST3_8agq5stscd7rth0x4nwkynnrf: i-signal-group=Develop_Rq_IMU_B_ST3_8agq5stscd7rth0x4nwkynnrf, packing-byte-order=little-endian, transfer-property=TRIGGERED
      frame DIAG_IMU_B_2F_ExtEth_RS_FD_ST3: id 0x18E16B80, from IMU_B, to IMU_A, frame-length=64, can-addressing-mode=EXTENDED, can-frame-rx-behavior=CAN-FD, can-frame-tx-behavior=CAN-FD  # Diagnoseanwort an ExtEth von IMU_B FD / Diagnostic Response to ExtEth from IMU_B FD
        n pdu DIAG_IMU_B_2F_ExtEth_RS_FD_ST3: length=64  # Diagnoseanwort an ExtEth von IMU_B FD / Diagnostic Response to ExtEth from IMU_B FD
      frame DIAG_IMU_B_2F_IntEth_RS_FD_ST3: id 0x18E16B85, from IMU_B, to IMU_A, frame-length=64, can-addressing-mode=EXTENDED, can-frame-rx-behavior=CAN-FD, can-frame-tx-behavior=CAN-FD  # Diagnoseanwort an IntEth von IMU_B FD / Diagnostic Response to IntEth from IMU_B FD
        n pdu DIAG_IMU_B_2F_IntEth_RS_FD_ST3: length=64  # Diagnoseanwort an IntEth von IMU_B FD / Diagnostic Response to IntEth from IMU_B FD
      frame DIAG_IMU_B_2F_ExtEth_RQ_FD_ST3: id 0x18E16B88, from IMU_A, to IMU_B, frame-length=64, can-addressing-mode=EXTENDED, can-frame-rx-behavior=CAN-FD, can-frame-tx-behavior=CAN-FD  # Diagnoseanfrage vom ExtEth für IMU_B FD / Diagnostic Request from ExtEth for IMU_B FD
        n pdu DIAG_IMU_B_2F_ExtEth_RQ_FD_ST3: length=64  # Diagnoseanfrage vom ExtEth für IMU_B FD / Diagnostic Request from ExtEth for IMU_B FD
      frame DIAG_IMU_B_2F_IntEth_RQ_FD_ST3: id 0x18E16B8D, from IMU_A, to IMU_B, frame-length=64, can-addressing-mode=EXTENDED, can-frame-rx-behavior=CAN-FD, can-frame-tx-behavior=CAN-FD  # Diagnoseanfrage vom IntEth für IMU_B FD / Diagnostic Request from IntEth for IMU_B FD
        n pdu DIAG_IMU_B_2F_IntEth_RQ_FD_ST3: length=64  # Diagnoseanfrage vom IntEth für IMU_B FD / Diagnostic Request from IntEth for IMU_B FD
      frame Meas_IMU_B_ST3: id 0x18E16B90, from IMU_B, frame-length=64, can-addressing-mode=EXTENDED, can-frame-rx-behavior=CAN-FD, can-frame-tx-behavior=CAN-FD  # Messbotschaft / Measurement
        pdu Meas_IMU_B_ST3: length=64, minimum-delay=0.02, transmission-mode-true-timing=event-controlled-timing=number-of-repetitions=0, unused-bit-pattern=0  # Messbotschaft / Measurement
          signal Meas_IMU_B_01_ST3: start 0, 8 bit, little-endian, data-type-policy=OVERRIDE, i-signal-type=PRIMITIVE, init-value=0, base-type=uint8, data-constr=c08_UInt_SNA_na  # Messsignal / Measurement
          signal Meas_IMU_B_02_ST3: start 8, 8 bit, little-endian, data-type-policy=OVERRIDE, i-signal-type=PRIMITIVE, init-value=0, base-type=uint8, data-constr=c08_UInt_SNA_na  # Messsignal / Measurement
          signal Meas_IMU_B_03_ST3: start 16, 8 bit, little-endian, data-type-policy=OVERRIDE, i-signal-type=PRIMITIVE, init-value=0, base-type=uint8, data-constr=c08_UInt_SNA_na  # Messsignal / Measurement
          signal Meas_IMU_B_04_ST3: start 24, 8 bit, little-endian, data-type-policy=OVERRIDE, i-signal-type=PRIMITIVE, init-value=0, base-type=uint8, data-constr=c08_UInt_SNA_na  # Messsignal / Measurement
          signal Meas_IMU_B_05_ST3: start 32, 8 bit, little-endian, data-type-policy=OVERRIDE, i-signal-type=PRIMITIVE, init-value=0, base-type=uint8, data-constr=c08_UInt_SNA_na  # Messsignal / Measurement
          signal Meas_IMU_B_06_ST3: start 40, 8 bit, little-endian, data-type-policy=OVERRIDE, i-signal-type=PRIMITIVE, init-value=0, base-type=uint8, data-constr=c08_UInt_SNA_na  # Messsignal / Measurement
          signal Meas_IMU_B_07_ST3: start 48, 8 bit, little-endian, data-type-policy=OVERRIDE, i-signal-type=PRIMITIVE, init-value=0, base-type=uint8, data-constr=c08_UInt_SNA_na  # Messsignal / Measurement
          signal Meas_IMU_B_08_ST3: start 56, 8 bit, little-endian, data-type-policy=OVERRIDE, i-signal-type=PRIMITIVE, init-value=0, base-type=uint8, data-constr=c08_UInt_SNA_na  # Messsignal / Measurement
          signal Meas_IMU_B_09_ST3: start 64, 8 bit, little-endian, data-type-policy=OVERRIDE, i-signal-type=PRIMITIVE, init-value=0, base-type=uint8, data-constr=c08_UInt_SNA_na  # Messsignal / Measurement
          signal Meas_IMU_B_10_ST3: start 72, 8 bit, little-endian, data-type-policy=OVERRIDE, i-signal-type=PRIMITIVE, init-value=0, base-type=uint8, data-constr=c08_UInt_SNA_na  # Messsignal / Measurement
          signal Meas_IMU_B_11_ST3: start 80, 8 bit, little-endian, data-type-policy=OVERRIDE, i-signal-type=PRIMITIVE, init-value=0, base-type=uint8, data-constr=c08_UInt_SNA_na  # Messsignal / Measurement
          signal Meas_IMU_B_12_ST3: start 88, 8 bit, little-endian, data-type-policy=OVERRIDE, i-signal-type=PRIMITIVE, init-value=0, base-type=uint8, data-constr=c08_UInt_SNA_na  # Messsignal / Measurement
          signal Meas_IMU_B_13_ST3: start 96, 8 bit, little-endian, data-type-policy=OVERRIDE, i-signal-type=PRIMITIVE, init-value=0, base-type=uint8, data-constr=c08_UInt_SNA_na  # Messsignal / Measurement
          signal Meas_IMU_B_14_ST3: start 104, 8 bit, little-endian, data-type-policy=OVERRIDE, i-signal-type=PRIMITIVE, init-value=0, base-type=uint8, data-constr=c08_UInt_SNA_na  # Messsignal / Measurement
          signal Meas_IMU_B_15_ST3: start 112, 8 bit, little-endian, data-type-policy=OVERRIDE, i-signal-type=PRIMITIVE, init-value=0, base-type=uint8, data-constr=c08_UInt_SNA_na  # Messsignal / Measurement
          signal Meas_IMU_B_16_ST3: start 120, 8 bit, little-endian, data-type-policy=OVERRIDE, i-signal-type=PRIMITIVE, init-value=0, base-type=uint8, data-constr=c08_UInt_SNA_na  # Messsignal / Measurement
          signal Meas_IMU_B_17_ST3: start 128, 8 bit, little-endian, data-type-policy=OVERRIDE, i-signal-type=PRIMITIVE, init-value=0, base-type=uint8, data-constr=c08_UInt_SNA_na  # Messsignal / Measurement
          signal Meas_IMU_B_18_ST3: start 136, 8 bit, little-endian, data-type-policy=OVERRIDE, i-signal-type=PRIMITIVE, init-value=0, base-type=uint8, data-constr=c08_UInt_SNA_na  # Messsignal / Measurement
          signal Meas_IMU_B_19_ST3: start 144, 8 bit, little-endian, data-type-policy=OVERRIDE, i-signal-type=PRIMITIVE, init-value=0, base-type=uint8, data-constr=c08_UInt_SNA_na  # Messsignal / Measurement
          signal Meas_IMU_B_20_ST3: start 152, 8 bit, little-endian, data-type-policy=OVERRIDE, i-signal-type=PRIMITIVE, init-value=0, base-type=uint8, data-constr=c08_UInt_SNA_na  # Messsignal / Measurement
          signal Meas_IMU_B_21_ST3: start 160, 8 bit, little-endian, data-type-policy=OVERRIDE, i-signal-type=PRIMITIVE, init-value=0, base-type=uint8, data-constr=c08_UInt_SNA_na  # Messsignal / Measurement
          signal Meas_IMU_B_22_ST3: start 168, 8 bit, little-endian, data-type-policy=OVERRIDE, i-signal-type=PRIMITIVE, init-value=0, base-type=uint8, data-constr=c08_UInt_SNA_na  # Messsignal / Measurement
          signal Meas_IMU_B_23_ST3: start 176, 8 bit, little-endian, data-type-policy=OVERRIDE, i-signal-type=PRIMITIVE, init-value=0, base-type=uint8, data-constr=c08_UInt_SNA_na  # Messsignal / Measurement
          signal Meas_IMU_B_24_ST3: start 184, 8 bit, little-endian, data-type-policy=OVERRIDE, i-signal-type=PRIMITIVE, init-value=0, base-type=uint8, data-constr=c08_UInt_SNA_na  # Messsignal / Measurement
          signal Meas_IMU_B_25_ST3: start 192, 8 bit, little-endian, data-type-policy=OVERRIDE, i-signal-type=PRIMITIVE, init-value=0, base-type=uint8, data-constr=c08_UInt_SNA_na  # Messsignal / Measurement
          signal Meas_IMU_B_26_ST3: start 200, 8 bit, little-endian, data-type-policy=OVERRIDE, i-signal-type=PRIMITIVE, init-value=0, base-type=uint8, data-constr=c08_UInt_SNA_na  # Messsignal / Measurement
          signal Meas_IMU_B_27_ST3: start 208, 8 bit, little-endian, data-type-policy=OVERRIDE, i-signal-type=PRIMITIVE, init-value=0, base-type=uint8, data-constr=c08_UInt_SNA_na  # Messsignal / Measurement
          signal Meas_IMU_B_28_ST3: start 216, 8 bit, little-endian, data-type-policy=OVERRIDE, i-signal-type=PRIMITIVE, init-value=0, base-type=uint8, data-constr=c08_UInt_SNA_na  # Messsignal / Measurement
          signal Meas_IMU_B_29_ST3: start 224, 8 bit, little-endian, data-type-policy=OVERRIDE, i-signal-type=PRIMITIVE, init-value=0, base-type=uint8, data-constr=c08_UInt_SNA_na  # Messsignal / Measurement
          signal Meas_IMU_B_30_ST3: start 232, 8 bit, little-endian, data-type-policy=OVERRIDE, i-signal-type=PRIMITIVE, init-value=0, base-type=uint8, data-constr=c08_UInt_SNA_na  # Messsignal / Measurement
          signal Meas_IMU_B_31_ST3: start 240, 8 bit, little-endian, data-type-policy=OVERRIDE, i-signal-type=PRIMITIVE, init-value=0, base-type=uint8, data-constr=c08_UInt_SNA_na  # Messsignal / Measurement
          signal Meas_IMU_B_32_ST3: start 248, 8 bit, little-endian, data-type-policy=OVERRIDE, i-signal-type=PRIMITIVE, init-value=0, base-type=uint8, data-constr=c08_UInt_SNA_na  # Messsignal / Measurement
          signal Meas_IMU_B_33_ST3: start 256, 8 bit, little-endian, data-type-policy=OVERRIDE, i-signal-type=PRIMITIVE, init-value=0, base-type=uint8, data-constr=c08_UInt_SNA_na  # Messsignal / Measurement
          signal Meas_IMU_B_34_ST3: start 264, 8 bit, little-endian, data-type-policy=OVERRIDE, i-signal-type=PRIMITIVE, init-value=0, base-type=uint8, data-constr=c08_UInt_SNA_na  # Messsignal / Measurement
          signal Meas_IMU_B_35_ST3: start 272, 8 bit, little-endian, data-type-policy=OVERRIDE, i-signal-type=PRIMITIVE, init-value=0, base-type=uint8, data-constr=c08_UInt_SNA_na  # Messsignal / Measurement
          signal Meas_IMU_B_36_ST3: start 280, 8 bit, little-endian, data-type-policy=OVERRIDE, i-signal-type=PRIMITIVE, init-value=0, base-type=uint8, data-constr=c08_UInt_SNA_na  # Messsignal / Measurement
          signal Meas_IMU_B_37_ST3: start 288, 8 bit, little-endian, data-type-policy=OVERRIDE, i-signal-type=PRIMITIVE, init-value=0, base-type=uint8, data-constr=c08_UInt_SNA_na  # Messsignal / Measurement
          signal Meas_IMU_B_38_ST3: start 296, 8 bit, little-endian, data-type-policy=OVERRIDE, i-signal-type=PRIMITIVE, init-value=0, base-type=uint8, data-constr=c08_UInt_SNA_na  # Messsignal / Measurement
          signal Meas_IMU_B_39_ST3: start 304, 8 bit, little-endian, data-type-policy=OVERRIDE, i-signal-type=PRIMITIVE, init-value=0, base-type=uint8, data-constr=c08_UInt_SNA_na  # Messsignal / Measurement
          signal Meas_IMU_B_40_ST3: start 312, 8 bit, little-endian, data-type-policy=OVERRIDE, i-signal-type=PRIMITIVE, init-value=0, base-type=uint8, data-constr=c08_UInt_SNA_na  # Messsignal / Measurement
          signal Meas_IMU_B_41_ST3: start 320, 8 bit, little-endian, data-type-policy=OVERRIDE, i-signal-type=PRIMITIVE, init-value=0, base-type=uint8, data-constr=c08_UInt_SNA_na  # Messsignal / Measurement
          signal Meas_IMU_B_42_ST3: start 328, 8 bit, little-endian, data-type-policy=OVERRIDE, i-signal-type=PRIMITIVE, init-value=0, base-type=uint8, data-constr=c08_UInt_SNA_na  # Messsignal / Measurement
          signal Meas_IMU_B_43_ST3: start 336, 8 bit, little-endian, data-type-policy=OVERRIDE, i-signal-type=PRIMITIVE, init-value=0, base-type=uint8, data-constr=c08_UInt_SNA_na  # Messsignal / Measurement
          signal Meas_IMU_B_44_ST3: start 344, 8 bit, little-endian, data-type-policy=OVERRIDE, i-signal-type=PRIMITIVE, init-value=0, base-type=uint8, data-constr=c08_UInt_SNA_na  # Messsignal / Measurement
          signal Meas_IMU_B_45_ST3: start 352, 8 bit, little-endian, data-type-policy=OVERRIDE, i-signal-type=PRIMITIVE, init-value=0, base-type=uint8, data-constr=c08_UInt_SNA_na  # Messsignal / Measurement
          signal Meas_IMU_B_46_ST3: start 360, 8 bit, little-endian, data-type-policy=OVERRIDE, i-signal-type=PRIMITIVE, init-value=0, base-type=uint8, data-constr=c08_UInt_SNA_na  # Messsignal / Measurement
          signal Meas_IMU_B_47_ST3: start 368, 8 bit, little-endian, data-type-policy=OVERRIDE, i-signal-type=PRIMITIVE, init-value=0, base-type=uint8, data-constr=c08_UInt_SNA_na  # Messsignal / Measurement
          signal Meas_IMU_B_48_ST3: start 376, 8 bit, little-endian, data-type-policy=OVERRIDE, i-signal-type=PRIMITIVE, init-value=0, base-type=uint8, data-constr=c08_UInt_SNA_na  # Messsignal / Measurement
          signal Meas_IMU_B_49_ST3: start 384, 8 bit, little-endian, data-type-policy=OVERRIDE, i-signal-type=PRIMITIVE, init-value=0, base-type=uint8, data-constr=c08_UInt_SNA_na  # Messsignal / Measurement
          signal Meas_IMU_B_50_ST3: start 392, 8 bit, little-endian, data-type-policy=OVERRIDE, i-signal-type=PRIMITIVE, init-value=0, base-type=uint8, data-constr=c08_UInt_SNA_na  # Messsignal / Measurement
          signal Meas_IMU_B_51_ST3: start 400, 8 bit, little-endian, data-type-policy=OVERRIDE, i-signal-type=PRIMITIVE, init-value=0, base-type=uint8, data-constr=c08_UInt_SNA_na  # Messsignal / Measurement
          signal Meas_IMU_B_52_ST3: start 408, 8 bit, little-endian, data-type-policy=OVERRIDE, i-signal-type=PRIMITIVE, init-value=0, base-type=uint8, data-constr=c08_UInt_SNA_na  # Messsignal / Measurement
          signal Meas_IMU_B_53_ST3: start 416, 8 bit, little-endian, data-type-policy=OVERRIDE, i-signal-type=PRIMITIVE, init-value=0, base-type=uint8, data-constr=c08_UInt_SNA_na  # Messsignal / Measurement
          signal Meas_IMU_B_54_ST3: start 424, 8 bit, little-endian, data-type-policy=OVERRIDE, i-signal-type=PRIMITIVE, init-value=0, base-type=uint8, data-constr=c08_UInt_SNA_na  # Messsignal / Measurement
          signal Meas_IMU_B_55_ST3: start 432, 8 bit, little-endian, data-type-policy=OVERRIDE, i-signal-type=PRIMITIVE, init-value=0, base-type=uint8, data-constr=c08_UInt_SNA_na  # Messsignal / Measurement
          signal Meas_IMU_B_56_ST3: start 440, 8 bit, little-endian, data-type-policy=OVERRIDE, i-signal-type=PRIMITIVE, init-value=0, base-type=uint8, data-constr=c08_UInt_SNA_na  # Messsignal / Measurement
          signal Meas_IMU_B_57_ST3: start 448, 8 bit, little-endian, data-type-policy=OVERRIDE, i-signal-type=PRIMITIVE, init-value=0, base-type=uint8, data-constr=c08_UInt_SNA_na  # Messsignal / Measurement
          signal Meas_IMU_B_58_ST3: start 456, 8 bit, little-endian, data-type-policy=OVERRIDE, i-signal-type=PRIMITIVE, init-value=0, base-type=uint8, data-constr=c08_UInt_SNA_na  # Messsignal / Measurement
          signal Meas_IMU_B_59_ST3: start 464, 8 bit, little-endian, data-type-policy=OVERRIDE, i-signal-type=PRIMITIVE, init-value=0, base-type=uint8, data-constr=c08_UInt_SNA_na  # Messsignal / Measurement
          signal Meas_IMU_B_60_ST3: start 472, 8 bit, little-endian, data-type-policy=OVERRIDE, i-signal-type=PRIMITIVE, init-value=0, base-type=uint8, data-constr=c08_UInt_SNA_na  # Messsignal / Measurement
          signal Meas_IMU_B_61_ST3: start 480, 8 bit, little-endian, data-type-policy=OVERRIDE, i-signal-type=PRIMITIVE, init-value=0, base-type=uint8, data-constr=c08_UInt_SNA_na  # Messsignal / Measurement
          signal Meas_IMU_B_62_ST3: start 488, 8 bit, little-endian, data-type-policy=OVERRIDE, i-signal-type=PRIMITIVE, init-value=0, base-type=uint8, data-constr=c08_UInt_SNA_na  # Messsignal / Measurement
          signal Meas_IMU_B_63_ST3: start 496, 8 bit, little-endian, data-type-policy=OVERRIDE, i-signal-type=PRIMITIVE, init-value=0, base-type=uint8, data-constr=c08_UInt_SNA_na  # Messsignal / Measurement
          signal Meas_IMU_B_64_ST3: start 504, 8 bit, little-endian, data-type-policy=OVERRIDE, i-signal-type=PRIMITIVE, init-value=0, base-type=uint8, data-constr=c08_UInt_SNA_na  # Messsignal / Measurement
          mapping Meas_IMU_B_ST3_9b4k5uqw790qkzbaaznvwy423: i-signal-group=Meas_IMU_B_ST3_9b4k5uqw790qkzbaaznvwy423, packing-byte-order=little-endian, transfer-property=TRIGGERED
      frame DIAG_RQ_GLOBAL_ExtEth_FD_ST3: id 0x18EEF888, from IMU_A, to IMU_B, frame-length=64, can-addressing-mode=EXTENDED, can-frame-rx-behavior=CAN-FD, can-frame-tx-behavior=CAN-FD  # Funktionaler Diagnose-Request vom Off-Board Tester (via Ethernet) / Functional Diagnostic Request from Off-Board Tester (via Ethernet)
        n pdu DIAG_RQ_GLOBAL_ExtEth_FD_ST3: length=64  # Funktionale Diagnoseanfrage (UDS) vom ExtEth FD / Functional Diagnostic Request (UDS) from ExtEth FD
      frame DIAG_RQ_GLOBAL_IntEth_FD_ST3: id 0x18EF0D8D, from IMU_A, to IMU_B, frame-length=64, can-addressing-mode=EXTENDED, can-frame-rx-behavior=CAN-FD, can-frame-tx-behavior=CAN-FD  # Funktionaler Diagnose-Request vom On-Board Tester (via Ethernet) / Functional Diagnostic Request from On-Board Tester (via Ethernet)
        n pdu DIAG_RQ_GLOBAL_IntEth_FD_ST3: length=64  # Funktionale Diagnoseanfrage (UDS) vom IntEth FD / Functional Diagnostic Request (UDS) from IntEth FD
      pdu triggering Ign_Stat_ST3_74u0yv4bzub4d7kkohk0jy10a: pdu=Ign_Stat_ST3, from IMU_A, to IMU_B
      pdu triggering IMU_A_Output_Fast_ST3_9j5x7ag429n202ymo68kf1vn0: pdu=IMU_A_Output_Fast_ST3, from IMU_A, to IMU_B
      pdu triggering BCS_Whl_Msg1_BTC_ST3_c16k4ur8udt67j57b0rf78j53: pdu=BCS_Whl_Msg1_BTC_ST3, from IMU_A, to IMU_B
      pdu triggering IMU_B_Output_ST3_71wg165b3j1a1mormsg5xnlfr: pdu=IMU_B_Output_ST3, from IMU_B, to IMU_A
      pdu triggering PT4_PTCoor4_ST3_831x3bc2a5f0b8lcc0rs7f0hl: pdu=PT4_PTCoor4_ST3, from IMU_A, to IMU_B
      pdu triggering PN14_Master_Stat1_ST3_2eb8i7df9hluel7u1vtmv4jbu: pdu=PN14_Master_Stat1_ST3, from IMU_A, to IMU_B
      pdu triggering SDU_DIAG_GLOBAL_ExtEth_RQ_IMU_INTERNAL_ST3_8oth9y18deizsgzcw8rxtafoj: pdu=SDU_DIAG_GLOBAL_ExtEth_RQ_IMU_INTERNAL_ST3, from IMU_A, to IMU_B
      pdu triggering SDU_DIAG_GLOBAL_IntEth_RQ_IMU_INTERNAL_ST3_21ocqvfmnzkv9x8f5nqo6bpa9: pdu=SDU_DIAG_GLOBAL_IntEth_RQ_IMU_INTERNAL_ST3, from IMU_A, to IMU_B
      pdu triggering SDU_DIAG_IMU_B_2F_ExtEth_RQ_IMU_INTERNAL_ST3_8p1t5axok0gymf7lxvm0d86r4: pdu=SDU_DIAG_IMU_B_2F_ExtEth_RQ_IMU_INTERNAL_ST3, from IMU_A, to IMU_B
      pdu triggering SDU_DIAG_IMU_B_2F_ExtEth_RS_IMU_INTERNAL_ST3_aj2z7r7k9dlwvjrbkwnnfkar5: pdu=SDU_DIAG_IMU_B_2F_ExtEth_RS_IMU_INTERNAL_ST3, from IMU_B, to IMU_A
      pdu triggering SDU_DIAG_IMU_B_2F_IntEth_RQ_IMU_INTERNAL_ST3_23a5ju54dx0yv2u8skz5uwmio: pdu=SDU_DIAG_IMU_B_2F_IntEth_RQ_IMU_INTERNAL_ST3, from IMU_A, to IMU_B
      pdu triggering SDU_DIAG_IMU_B_2F_IntEth_RS_IMU_INTERNAL_ST3_aim5b9uh4cxdhsdi0njtzfqhq: pdu=SDU_DIAG_IMU_B_2F_IntEth_RS_IMU_INTERNAL_ST3, from IMU_B, to IMU_A
package /NmConfigs
  nm config NM_CONFIG: can-nm-cluster-coupling{coupled-cluster=IMU_INTERNAL, nm-busload-reduction-enabled=false, nm-immediate-restart-enabled=false}
    can nm cluster IMU_INTERNAL:
      communication-cluster=IMU_INTERNAL
      nm-channel-id=47
      nm-channel-sleep-master=false
      nm-pnc-participation=true
      nm-synchronizing-network=false
      nm-busload-reduction-active=false
      nm-cbv-position=0
      nm-immediate-nm-cycle-time=0.02
      nm-immediate-nm-transmissions=6
      nm-message-timeout-time=0.5
      nm-msg-cycle-time=1.0
      nm-network-timeout=2.5
      nm-remote-sleep-indication-time=2.5
      nm-repeat-message-time=3.0
      nm-wait-bus-sleep-time=1.5
      can nm node IMU_A_IMU_INTERNALNMNODE: controller=IMU_A_IMU_INTERNAL, nm-if-ecu=IMU_A_CAN_NMECU, nm-passive-mode-enabled=false, rx-nm-pdu=NM_Dummy_ST3, tx-nm-pdu=NM_IMU_A_ST3, nm-msg-cycle-offset=0.0
      can nm node IMU_B_IMU_INTERNALNMNODE: controller=IMU_B_IMU_INTERNAL, nm-if-ecu=IMU_B_CAN_NMECU, nm-passive-mode-enabled=false, rx-nm-pdu=NM_Dummy_ST3, tx-nm-pdu=NM_IMU_B_ST3, nm-msg-cycle-offset=0.0
    nm-if-ecus:
      nm ecu IMU_A_CAN_NMECU: ecu-instance=IMU_A, nm-com-control-enabled=true, nm-remote-sleep-ind-enabled=true, nm-user-data-enabled=false
      nm ecu IMU_B_CAN_NMECU: ecu-instance=IMU_B, nm-com-control-enabled=true, nm-remote-sleep-ind-enabled=true, nm-user-data-enabled=false
package /ISignalIPduGroups/IMU_INTERNAL/PKG_IMU_INTERNAL
  15 x i signal i pdu group:
    IMU_A_IMU_INTERNAL_Tx_PNC_All_Active: communication-direction=OUT, communication-mode=Partial Network
      i-signal-i-pdus:
        BCS_Whl_Msg1_BTC_ST3
        DI_OdoSpeedometer_ST3
        DIAG_Stat_ST3
        ECU_Stat_IMU_A_IMU_INTERNAL_ST3
        FBL_Cfg_Star3_ST3
        Ign_Stat_ST3
        IMU_A_Output_Fast_ST3
        PN14_Master_Stat1_ST3
        PT4_PTCoor4_ST3
        VSS_TP_Auth_ST3
        VSS_TP_RealTmOffset_ST3
        VSS_TP_SecTickCount_Lvl1_ST3
        VSS_TP_SharedSecret_ST3
        VSS_TP_VIN_ST3
    IMU_A_IMU_INTERNAL_Tx_PNC_15_ComCtrl: communication-direction=OUT, communication-mode=Partial Network
      i-signal-i-pdus:
        DI_OdoSpeedometer_ST3
        Ign_Stat_ST3
        PN14_Master_Stat1_ST3
        VSS_TP_Auth_ST3
        VSS_TP_RealTmOffset_ST3
        VSS_TP_SecTickCount_Lvl1_ST3
        VSS_TP_SharedSecret_ST3
        VSS_TP_VIN_ST3
    IMU_A_IMU_INTERNAL_Tx_PNC_20: communication-direction=OUT, communication-mode=Partial Network
      i-signal-i-pdus:
        BCS_Whl_Msg1_BTC_ST3
        DI_OdoSpeedometer_ST3
        DIAG_Stat_ST3
        ECU_Stat_IMU_A_IMU_INTERNAL_ST3
        FBL_Cfg_Star3_ST3
        Ign_Stat_ST3
        IMU_A_Output_Fast_ST3
        PN14_Master_Stat1_ST3
        PT4_PTCoor4_ST3
        VSS_TP_Auth_ST3
        VSS_TP_RealTmOffset_ST3
        VSS_TP_SecTickCount_Lvl1_ST3
        VSS_TP_SharedSecret_ST3
        VSS_TP_VIN_ST3
    IMU_A_IMU_INTERNAL_Tx_PNC_23: communication-direction=OUT, communication-mode=Partial Network
      i-signal-i-pdus:
        BCS_Whl_Msg1_BTC_ST3
        DI_OdoSpeedometer_ST3
        DIAG_Stat_ST3
        ECU_Stat_IMU_A_IMU_INTERNAL_ST3
        Ign_Stat_ST3
        IMU_A_Output_Fast_ST3
        PN14_Master_Stat1_ST3
        PT4_PTCoor4_ST3
        VSS_TP_Auth_ST3
        VSS_TP_RealTmOffset_ST3
        VSS_TP_SecTickCount_Lvl1_ST3
        VSS_TP_SharedSecret_ST3
        VSS_TP_VIN_ST3
    TxMess_IMU_B_IMU_INTERNAL: communication-direction=OUT, communication-mode=Measurement, i-signal-i-pdus=[Develop_Rs_IMU_B_ST3, Meas_IMU_B_ST3]
    IMU_B_IMU_INTERNAL_Tx_PNC_All_Active: communication-direction=OUT, communication-mode=Partial Network, i-signal-i-pdus=[ECU_Stat_IMU_B_ST3, IMU_B_Output_ST3, ROE_IMU_B_ST3]
    IMU_B_IMU_INTERNAL_Tx_PNC_20: communication-direction=OUT, communication-mode=Partial Network, i-signal-i-pdus=[ECU_Stat_IMU_B_ST3, IMU_B_Output_ST3, ROE_IMU_B_ST3]
    IMU_B_IMU_INTERNAL_Tx_PNC_23: communication-direction=OUT, communication-mode=Partial Network, i-signal-i-pdus=[ECU_Stat_IMU_B_ST3, ROE_IMU_B_ST3]
    IMU_A_IMU_INTERNAL_Rx_PNC_All_Active: communication-direction=IN, communication-mode=Partial Network, i-signal-i-pdus=[ECU_Stat_IMU_B_ST3, IMU_B_Output_ST3, ROE_IMU_B_ST3]
    IMU_A_IMU_INTERNAL_Rx_PNC_20: communication-direction=IN, communication-mode=Partial Network, i-signal-i-pdus=[ECU_Stat_IMU_B_ST3, IMU_B_Output_ST3, ROE_IMU_B_ST3]
    IMU_A_IMU_INTERNAL_Rx_PNC_23: communication-direction=IN, communication-mode=Partial Network, i-signal-i-pdus=[ECU_Stat_IMU_B_ST3, ROE_IMU_B_ST3]
    IMU_B_IMU_INTERNAL_Rx_PNC_All_Active: communication-direction=IN, communication-mode=Partial Network
      i-signal-i-pdus:
        BCS_Whl_Msg1_BTC_ST3
        Develop_Rq_IMU_B_ST3
        DI_OdoSpeedometer_ST3
        DIAG_Stat_ST3
        FBL_Cfg_Star3_ST3
        Ign_Stat_ST3
        IMU_A_Output_Fast_ST3
        PN14_Master_Stat1_ST3
        PT4_PTCoor4_ST3
        VSS_TP_Auth_ST3
        VSS_TP_RealTmOffset_ST3
        VSS_TP_SecTickCount_Lvl1_ST3
        VSS_TP_SharedSecret_ST3
        VSS_TP_VIN_ST3
    IMU_B_IMU_INTERNAL_Rx_PNC_15_ComCtrl: communication-direction=IN, communication-mode=Partial Network
      i-signal-i-pdus:
        DI_OdoSpeedometer_ST3
        Ign_Stat_ST3
        PN14_Master_Stat1_ST3
        VSS_TP_Auth_ST3
        VSS_TP_RealTmOffset_ST3
        VSS_TP_SecTickCount_Lvl1_ST3
        VSS_TP_SharedSecret_ST3
        VSS_TP_VIN_ST3
    IMU_B_IMU_INTERNAL_Rx_PNC_20: communication-direction=IN, communication-mode=Partial Network
      i-signal-i-pdus:
        BCS_Whl_Msg1_BTC_ST3
        Develop_Rq_IMU_B_ST3
        DI_OdoSpeedometer_ST3
        DIAG_Stat_ST3
        FBL_Cfg_Star3_ST3
        Ign_Stat_ST3
        IMU_A_Output_Fast_ST3
        PN14_Master_Stat1_ST3
        PT4_PTCoor4_ST3
        VSS_TP_Auth_ST3
        VSS_TP_RealTmOffset_ST3
        VSS_TP_SecTickCount_Lvl1_ST3
        VSS_TP_SharedSecret_ST3
        VSS_TP_VIN_ST3
    IMU_B_IMU_INTERNAL_Rx_PNC_23: communication-direction=IN, communication-mode=Partial Network
      i-signal-i-pdus:
        BCS_Whl_Msg1_BTC_ST3
        DI_OdoSpeedometer_ST3
        DIAG_Stat_ST3
        Ign_Stat_ST3
        IMU_A_Output_Fast_ST3
        PN14_Master_Stat1_ST3
        PT4_PTCoor4_ST3
        VSS_TP_Auth_ST3
        VSS_TP_RealTmOffset_ST3
        VSS_TP_SecTickCount_Lvl1_ST3
        VSS_TP_SharedSecret_ST3
        VSS_TP_VIN_ST3
package /TpConfigs/IMU_INTERNAL
  can tp config IMU_INTERNAL: communication-cluster=IMU_INTERNAL, tp-ecus=[IMU_A, IMU_B]
    6 x can tp address:
      TPA_0ef8h: tp-address=3832
      TPA_0f0dh: tp-address=3853
      TPA_116bh: tp-address=4459
      TPA_eef8h: tp-address=61176
      TPA_ef0dh: tp-address=61197
      TPA_0441h: tp-address=1089
    4 x can tp channel, all with channel-id=47:
      IMU_INTERNAL_DIAG_GLOBAL_ExtEth_RQ_IMU_INTERNAL_ST3
      IMU_INTERNAL_DIAG_GLOBAL_IntEth_RQ_IMU_INTERNAL_ST3
      IMU_INTERNAL_DIAG_IMU_B_2F_ExtEth_RQ_IMU_INTERNAL_ST3_DIAG_IMU_B_2F_ExtEth_RS_IMU_INTERNAL_ST3
      IMU_INTERNAL_DIAG_IMU_B_2F_IntEth_RQ_IMU_INTERNAL_ST3_DIAG_IMU_B_2F_IntEth_RS_IMU_INTERNAL_ST3
    can-tp-connection addressing-format=STANDARD, can-tp-channel=IMU_INTERNAL_DIAG_GLOBAL_ExtEth_RQ_IMU_INTERNAL_ST3, data-pdu=DIAG_RQ_GLOBAL_ExtEth_FD_ST3, max-block-size=0, multicast=TPA_0441h, padding-activation=true, receiver=TPN_TPA_eef8h_bnz9u49h9o8tdsshqha4tr1i9, ta-type=FUNCTIONAL-CAN-FD, tp-sdu=SDU_DIAG_GLOBAL_ExtEth_RQ_IMU_INTERNAL_ST3, transmitter=TPN_TPA_0ef8h_a236o30eeudwaafi6be18acb1:
      ident DIAG_GLOBAL_ExtEth_RQ_IMU_INTERNAL_ST3
    can-tp-connection addressing-format=STANDARD, can-tp-channel=IMU_INTERNAL_DIAG_GLOBAL_IntEth_RQ_IMU_INTERNAL_ST3, data-pdu=DIAG_RQ_GLOBAL_IntEth_FD_ST3, max-block-size=0, multicast=TPA_0441h, padding-activation=true, receiver=TPN_TPA_ef0dh_ckhhnyd9kl0ze4rtfhpcg52sk, ta-type=FUNCTIONAL-CAN-FD, tp-sdu=SDU_DIAG_GLOBAL_IntEth_RQ_IMU_INTERNAL_ST3, transmitter=TPN_TPA_0f0dh_8y8goi884hwsgwjxwct7j2aip:
      ident DIAG_GLOBAL_IntEth_RQ_IMU_INTERNAL_ST3
    can-tp-connection addressing-format=STANDARD, can-tp-channel=IMU_INTERNAL_DIAG_IMU_B_2F_ExtEth_RQ_IMU_INTERNAL_ST3_DIAG_IMU_B_2F_ExtEth_RS_IMU_INTERNAL_ST3, data-pdu=DIAG_IMU_B_2F_ExtEth_RQ_FD_ST3, flow-control-pdu=DIAG_IMU_B_2F_ExtEth_RS_FD_ST3, max-block-size=0, padding-activation=true, receiver=TPN_TPA_116bh_akdkhnwqg3biom8ujoflnhlu3, ta-type=PHYSICAL-CAN-FD, tp-sdu=SDU_DIAG_IMU_B_2F_ExtEth_RQ_IMU_INTERNAL_ST3, transmitter=TPN_TPA_0ef8h_a236o30eeudwaafi6be18acb1:
      ident DIAG_IMU_B_2F_ExtEth_RQ_IMU_INTERNAL_ST3
    can-tp-connection addressing-format=STANDARD, can-tp-channel=IMU_INTERNAL_DIAG_IMU_B_2F_ExtEth_RQ_IMU_INTERNAL_ST3_DIAG_IMU_B_2F_ExtEth_RS_IMU_INTERNAL_ST3, data-pdu=DIAG_IMU_B_2F_ExtEth_RS_FD_ST3, flow-control-pdu=DIAG_IMU_B_2F_ExtEth_RQ_FD_ST3, max-block-size=1, padding-activation=true, receiver=TPN_TPA_0ef8h_a236o30eeudwaafi6be18acb1, ta-type=PHYSICAL-CAN-FD, tp-sdu=SDU_DIAG_IMU_B_2F_ExtEth_RS_IMU_INTERNAL_ST3, transmitter=TPN_TPA_116bh_akdkhnwqg3biom8ujoflnhlu3:
      ident DIAG_IMU_B_2F_ExtEth_RS_IMU_INTERNAL_ST3
    can-tp-connection addressing-format=STANDARD, can-tp-channel=IMU_INTERNAL_DIAG_IMU_B_2F_IntEth_RQ_IMU_INTERNAL_ST3_DIAG_IMU_B_2F_IntEth_RS_IMU_INTERNAL_ST3, data-pdu=DIAG_IMU_B_2F_IntEth_RQ_FD_ST3, flow-control-pdu=DIAG_IMU_B_2F_IntEth_RS_FD_ST3, max-block-size=0, padding-activation=true, receiver=TPN_TPA_116bh_akdkhnwqg3biom8ujoflnhlu3, ta-type=PHYSICAL-CAN-FD, tp-sdu=SDU_DIAG_IMU_B_2F_IntEth_RQ_IMU_INTERNAL_ST3, transmitter=TPN_TPA_0f0dh_8y8goi884hwsgwjxwct7j2aip:
      ident DIAG_IMU_B_2F_IntEth_RQ_IMU_INTERNAL_ST3
    can-tp-connection addressing-format=STANDARD, can-tp-channel=IMU_INTERNAL_DIAG_IMU_B_2F_IntEth_RQ_IMU_INTERNAL_ST3_DIAG_IMU_B_2F_IntEth_RS_IMU_INTERNAL_ST3, data-pdu=DIAG_IMU_B_2F_IntEth_RS_FD_ST3, flow-control-pdu=DIAG_IMU_B_2F_IntEth_RQ_FD_ST3, max-block-size=1, padding-activation=true, receiver=TPN_TPA_0f0dh_8y8goi884hwsgwjxwct7j2aip, ta-type=PHYSICAL-CAN-FD, tp-sdu=SDU_DIAG_IMU_B_2F_IntEth_RS_IMU_INTERNAL_ST3, transmitter=TPN_TPA_116bh_akdkhnwqg3biom8ujoflnhlu3:
      ident DIAG_IMU_B_2F_IntEth_RS_IMU_INTERNAL_ST3
    5 x can tp node:
      TPN_TPA_0ef8h_a236o30eeudwaafi6be18acb1: connector=IMU_A_IMU_INTERNAL_6hr0dxrs6bxnusth9n7j0x4yv, st-min=0.01, tp-address=TPA_0ef8h
      TPN_TPA_0f0dh_8y8goi884hwsgwjxwct7j2aip: connector=IMU_A_IMU_INTERNAL_6hr0dxrs6bxnusth9n7j0x4yv, st-min=0.01, tp-address=TPA_0f0dh
      TPN_TPA_116bh_akdkhnwqg3biom8ujoflnhlu3: connector=IMU_B_IMU_INTERNAL_949amicgr3ot53d5rms7k8b3w, st-min=0.01, tp-address=TPA_116bh
      TPN_TPA_eef8h_bnz9u49h9o8tdsshqha4tr1i9: connector=IMU_B_IMU_INTERNAL_949amicgr3ot53d5rms7k8b3w, tp-address=TPA_eef8h
      TPN_TPA_ef0dh_ckhhnyd9kl0ze4rtfhpcg52sk: connector=IMU_B_IMU_INTERNAL_949amicgr3ot53d5rms7k8b3w, tp-address=TPA_ef0dh
package /DiagnosticConnections/IMU_INTERNAL/PKG_IMU_INTERNAL
  diagnostic connection DIAG_IMU_B_2F_ExtEth_RQ_IMU_INTERNAL_ST3_DIAG_IMU_B_2F_ExtEth_RS_IMU_INTERNAL_ST3: functional-request=DIAG_GLOBAL_ExtEth_RQ_IMU_INTERNAL_ST3, physical-request=DIAG_IMU_B_2F_ExtEth_RQ_IMU_INTERNAL_ST3, response=DIAG_IMU_B_2F_ExtEth_RS_IMU_INTERNAL_ST3
  diagnostic connection DIAG_IMU_B_2F_IntEth_RQ_IMU_INTERNAL_ST3_DIAG_IMU_B_2F_IntEth_RS_IMU_INTERNAL_ST3: functional-request=DIAG_GLOBAL_IntEth_RQ_IMU_INTERNAL_ST3, physical-request=DIAG_IMU_B_2F_IntEth_RQ_IMU_INTERNAL_ST3, response=DIAG_IMU_B_2F_IntEth_RS_IMU_INTERNAL_ST3
package /GlobalTimeDomains
  global time domain GTD_IMU_INTERNAL_0: category=SYNCHRONIZED, debounce-time=0.04, domain-id=0, global-time-domain-propertys=can-global-time-domain-props={fup-data-id-lists=[143, 78, 13, 199, 134, 69, 4, 190, 125, 60, 246, 181, 116, 51, 237, 172], sync-data-id-lists=[225, 102, 230, 107, 235, 112, 240, 117, 245, 122, 250, 127, 4, 132, 9, 137]}, pdu-triggerings=GTS_Main_CAN_ST3_428sgbpm49c8u4bnahw7npgnf, sync-loss-timeout=1.75  # IMU_INTERNAL
    global-time-masters:
      global time can master GTM_IMU_A_0: communication-connector=IMU_A_IMU_INTERNAL_6hr0dxrs6bxnusth9n7j0x4yv, immediate-resume-time=0.7, is-system-wide-global-time-master=false, sync-period=0.5, crc-secured=CRC-SUPPORTED, sync-confirmation-timeout=0.2  # IMU_A
    global time can slave GTS_IMU_B_0: communication-connector=IMU_B_IMU_INTERNAL_949amicgr3ot53d5rms7k8b3w, follow-up-timeout-value=0.25, time-leap-future-threshold=0.0017, time-leap-healing-counter=3, time-leap-past-threshold=0.0017, crc-validated=CRC-VALIDATED, sequence-counter-jump-width=3  # IMU_B
package /Systems
  system SYSTEM_XDIS: category=SYSTEM_EXTRACT, container-i-pdu-header-byte-order=big-endian, pnc-vector-length=7, pnc-vector-offset=1, system-version=2024.05.00
    system mapping XDIS_SYSTEMMAPPING
      6 x sec oc crypto service mapping, all with authentication=CMAC_AES_128:
        SECPDU_BCS_Whl_Msg1_BTC_ST3: crypto-service-key=CSK_1270CRYPTO_ALGOFAM_AES128
        SECPDU_Ign_Stat_ST3: crypto-service-key=CSK_28212CRYPTO_ALGOFAM_AES128
        SECPDU_IMU_A_Output_Fast_ST3: crypto-service-key=CSK_38379CRYPTO_ALGOFAM_AES128
        SECPDU_IMU_B_Output_ST3: crypto-service-key=CSK_46116CRYPTO_ALGOFAM_AES128
        SECPDU_PN14_Master_Stat1_ST3: crypto-service-key=CSK_57668CRYPTO_ALGOFAM_AES128
        SECPDU_PT4_PTCoor4_ST3: crypto-service-key=CSK_26743CRYPTO_ALGOFAM_AES128
      pnc-mapping physical-channel=IMU_INTERNAL, pnc-group=[IMU_A_IMU_INTERNAL_Rx_PNC_All_Active, IMU_A_IMU_INTERNAL_Tx_PNC_All_Active, IMU_B_IMU_INTERNAL_Rx_PNC_All_Active, IMU_B_IMU_INTERNAL_Tx_PNC_All_Active], pnc-identifier=8, pnc-wakeup-enable=true, wakeup-frame=[NM_IMU_A_ST3_6vo2o7b9cyd47cbahjaygi9t7, NM_IMU_B_ST3_6a4t4fydo7fjdt7az7m07uidc]:
        ident PNC_00_MAPPING
      pnc-mapping physical-channel=IMU_INTERNAL, pnc-group=[IMU_A_IMU_INTERNAL_Tx_PNC_15_ComCtrl, IMU_B_IMU_INTERNAL_Rx_PNC_15_ComCtrl], pnc-identifier=23, pnc-wakeup-enable=true, wakeup-frame=[NM_IMU_A_ST3_6vo2o7b9cyd47cbahjaygi9t7, NM_IMU_B_ST3_6a4t4fydo7fjdt7az7m07uidc]:
        ident PNC_15_MAPPING
      pnc-mapping physical-channel=IMU_INTERNAL, pnc-group=[IMU_A_IMU_INTERNAL_Rx_PNC_20, IMU_A_IMU_INTERNAL_Tx_PNC_20, IMU_B_IMU_INTERNAL_Rx_PNC_20, IMU_B_IMU_INTERNAL_Tx_PNC_20], pnc-identifier=28, pnc-wakeup-enable=true, wakeup-frame=[NM_IMU_A_ST3_6vo2o7b9cyd47cbahjaygi9t7, NM_IMU_B_ST3_6a4t4fydo7fjdt7az7m07uidc]:
        ident PNC_20_MAPPING
      pnc-mapping physical-channel=IMU_INTERNAL, pnc-group=[IMU_A_IMU_INTERNAL_Rx_PNC_23, IMU_A_IMU_INTERNAL_Tx_PNC_23, IMU_B_IMU_INTERNAL_Rx_PNC_23, IMU_B_IMU_INTERNAL_Tx_PNC_23], pnc-identifier=31, pnc-wakeup-enable=true, wakeup-frame=[NM_IMU_A_ST3_6vo2o7b9cyd47cbahjaygi9t7, NM_IMU_B_ST3_6a4t4fydo7fjdt7az7m07uidc]:
        ident PNC_23_MAPPING
package /CryptoPrimitives
  crypto service primitive CMAC_AES_128: algorithm-family=CRYPTO_ALGOFAM_AES, algorithm-mode=CRYPTO_ALGOMODE_CMAC
package /CryptoDevelopmentKeys
  6 x crypto service key, all with algorithm-family=CRYPTO_ALGOFAM_AES, length=128:
    CSK_1270CRYPTO_ALGOFAM_AES128
    CSK_28212CRYPTO_ALGOFAM_AES128
    CSK_38379CRYPTO_ALGOFAM_AES128
    CSK_46116CRYPTO_ALGOFAM_AES128
    CSK_57668CRYPTO_ALGOFAM_AES128
    CSK_26743CRYPTO_ALGOFAM_AES128
